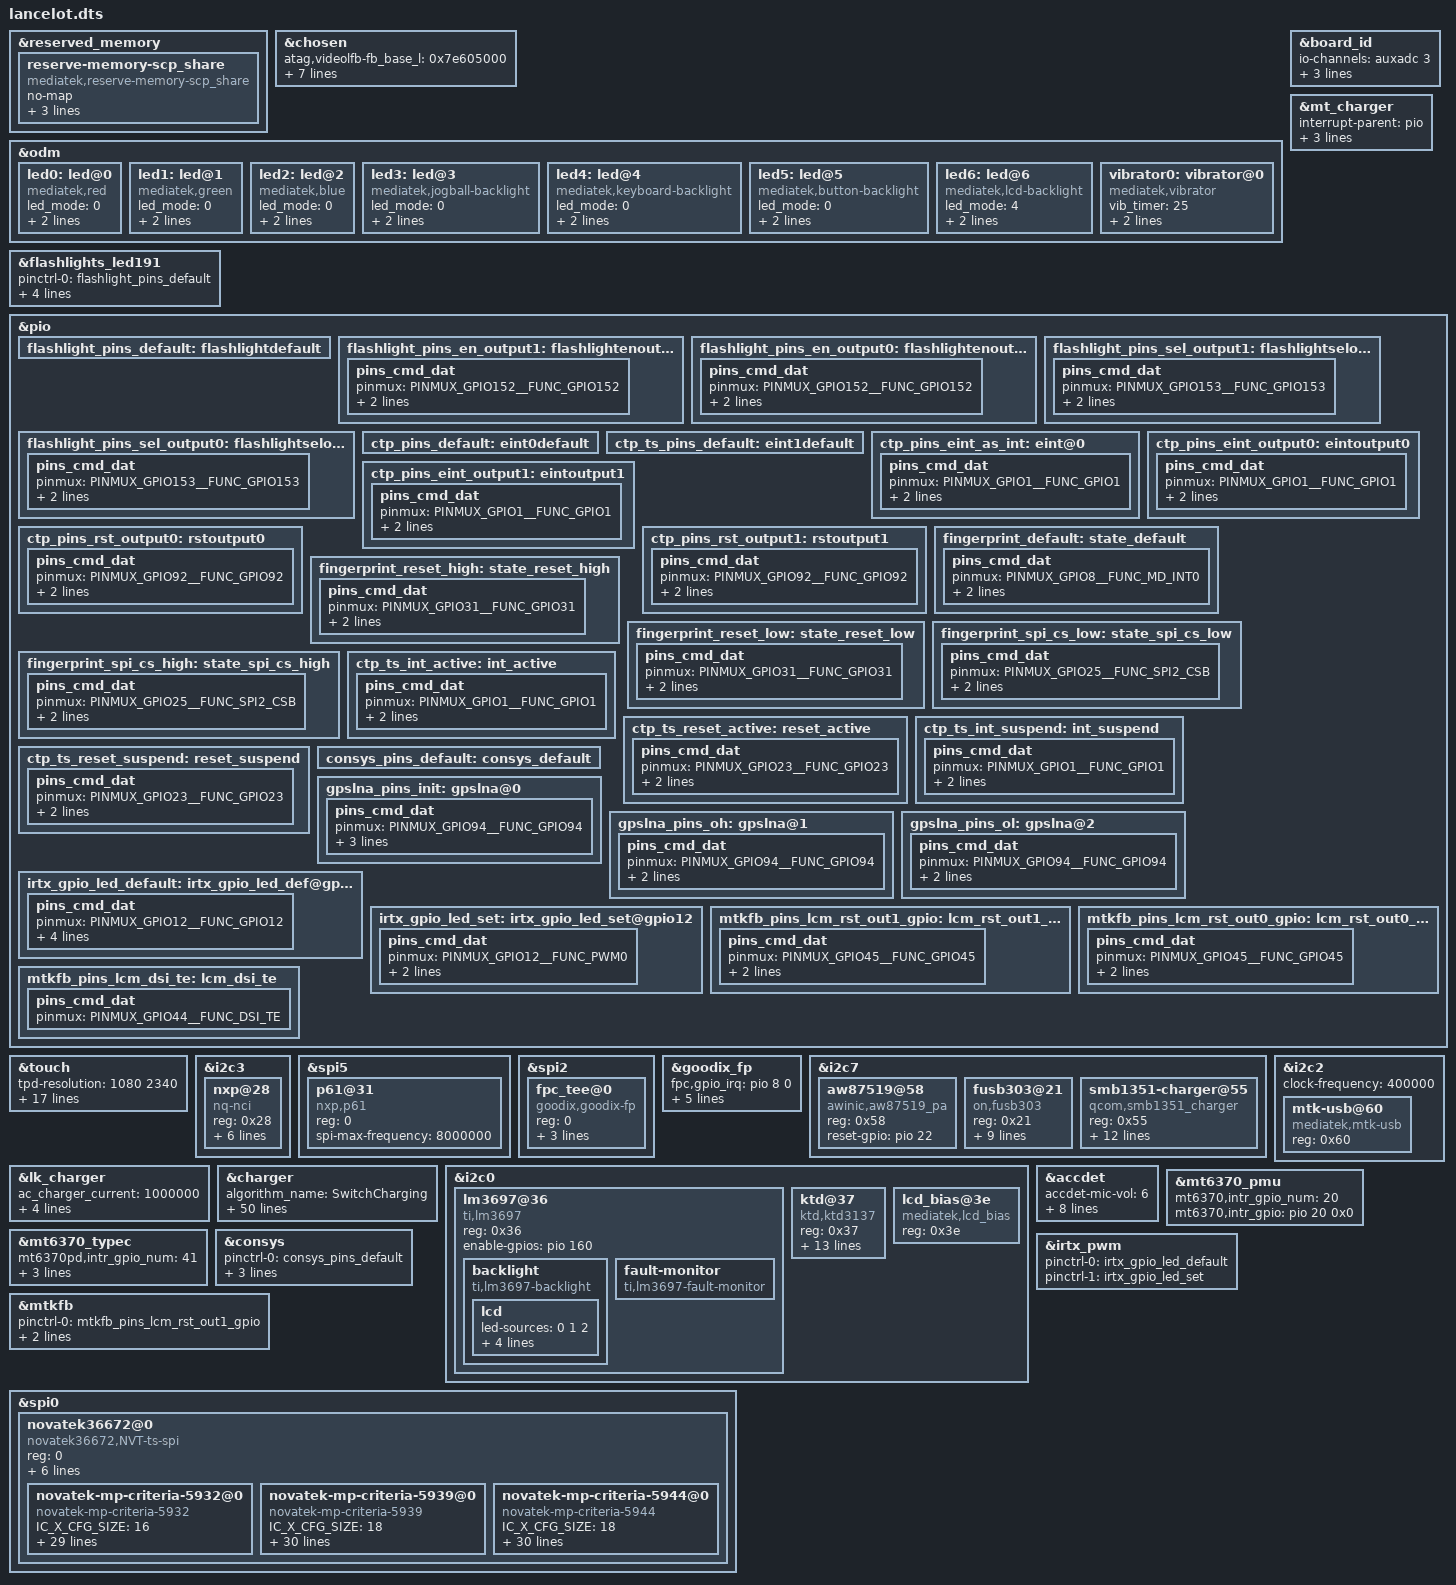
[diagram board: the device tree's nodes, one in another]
/*
 * Copyright (C) 2019 MediaTek Inc.
 *
 * This program is free software; you can redistribute it and/or modify
 * it under the terms of the GNU General Public License version 2 as
 * published by the Free Software Foundation.
 *
 * This program is distributed in the hope that it will be useful,
 * but WITHOUT ANY WARRANTY; without even the implied warranty of
 * MERCHANTABILITY or FITNESS FOR A PARTICULAR PURPOSE.
 * See http://www.gnu.org/licenses/gpl-2.0.html for more details.
 */

/dts-v1/;
/plugin/;
#include <dt-bindings/interrupt-controller/irq.h>
#include <dt-bindings/interrupt-controller/arm-gic.h>
#include <dt-bindings/pinctrl/mt6768-pinfunc.h>

&reserved_memory {
	reserve-memory-scp_share {
		compatible = "mediatek,reserve-memory-scp_share";
		no-map;
		size = <0 0x00d00000>;
		alignment = <0 0x1000000>;
		alloc-ranges = <0 0x40000000 0 0x50000000>;
	};
};

/* chosen */
&chosen {

	atag,videolfb-fb_base_l = <0x7e605000>;
	atag,videolfb-fb_base_h = <0x0>;
	atag,videolfb-islcmfound = <1>;
	atag,videolfb-islcm_inited = <0>;
	atag,videolfb-fps= <6000>;
	atag,videolfb-vramSize= <0x017e8000>;
	atag,videolfb-lcmname=
		"hx83112b_fhdp_dsi_cmd_auo_rt5081_drv";
};

&odm {
	led0:led@0 {
		compatible = "mediatek,red";
		led_mode = <0>;
		data = <1>;
		pwm_config = <0 0 0 0 0>;
	};
	led1:led@1 {
		compatible = "mediatek,green";
		led_mode = <0>;
		data = <1>;
		pwm_config = <0 0 0 0 0>;
	};
	led2:led@2 {
		compatible = "mediatek,blue";
		led_mode = <0>;
		data = <1>;
		pwm_config = <0 0 0 0 0>;
	};
	led3:led@3 {
		compatible = "mediatek,jogball-backlight";
		led_mode = <0>;
		data = <1>;
		pwm_config = <0 0 0 0 0>;
	};
	led4:led@4 {
		compatible = "mediatek,keyboard-backlight";
		led_mode = <0>;
		data = <1>;
		pwm_config = <0 0 0 0 0>;
	};
	led5:led@5 {
		compatible = "mediatek,button-backlight";
		led_mode = <0>;
		data = <1>;
		pwm_config = <0 0 0 0 0>;
	};
	led6:led@6 {
		compatible = "mediatek,lcd-backlight";
		led_mode = <4>;
		data = <1>;
		pwm_config = <0 3 0 0 0>;
	};
	vibrator0:vibrator@0 {
		compatible = "mediatek,vibrator";
		vib_timer = <25>;
		vib_limit = <9>;
		vib_vol= <11>;
	};
};

&board_id {
	io-channels = <&auxadc 3>;
	io-channel-names = "board_id-channel";
	hw_id-gpios = <&pio 158 0>;
	board_id2-gpios = <&pio 5 0>;
	board_id3-gpios = <&pio 6 0>;
	status = "okay";
};

&mt_charger {
	interrupt-parent = <&pio>;
	reverse-gpio = <&pio 91 0>;
	pinctrl-names = "reverse_high", "reverse_low";
	pinctrl-0 = <&reverse_high>;
	pinctrl-1 = <&reverse_low>;
};
/* flashlight start */
&flashlights_led191 {
	pinctrl-names = "default", "hw_ch0_high",
		"hw_ch0_low", "hw_ch1_high",
		"hw_ch1_low";
	pinctrl-0 = <&flashlight_pins_default>;
	pinctrl-1 = <&flashlight_pins_en_output1>;
	pinctrl-2 = <&flashlight_pins_en_output0>;
	pinctrl-3 = <&flashlight_pins_sel_output1>;
	pinctrl-4 = <&flashlight_pins_sel_output0>;
	status = "okay";
};
&pio {
	flashlight_pins_default: flashlightdefault {
	};
	flashlight_pins_en_output1: flashlightenoutput1 {
		pins_cmd_dat {
			pinmux = <PINMUX_GPIO152__FUNC_GPIO152>;
			slew-rate = <1>;
			output-high;
		};
	};
	flashlight_pins_en_output0: flashlightenoutput0 {
		pins_cmd_dat {
			pinmux = <PINMUX_GPIO152__FUNC_GPIO152>;
			slew-rate = <1>;
			output-low;
		};
	};
	flashlight_pins_sel_output1: flashlightseloutput1 {
		pins_cmd_dat {
			pinmux = <PINMUX_GPIO153__FUNC_GPIO153>;
			slew-rate = <1>;
			output-high;
		};
	};
	flashlight_pins_sel_output0: flashlightseloutput0 {
		pins_cmd_dat {
			pinmux = <PINMUX_GPIO153__FUNC_GPIO153>;
			slew-rate = <1>;
			output-low;
		};
	};
};
/* flashlight end*/
/* TOUCH start */
&touch {
	tpd-resolution = <1080 2340>;
	use-tpd-button = <0>;
	tpd-key-num = <3>;
	tpd-key-local= <139 172 158 0>;
	tpd-key-dim-local = <90 883 100 40 230
				883 100 40 370 883 100 40 0 0 0 0>;
	tpd-max-touch-num = <10>;
	tpd-filter-enable = <0>;
	tpd-filter-pixel-density = <168>;
	tpd-filter-custom-prameters = <0 0 0 0 0 0 0 0 0 0 0 0>;
	tpd-filter-custom-speed = <0 0 0>;
	pinctrl-names = "default", "state_eint_as_int",
		"state_eint_output0", "state_eint_output1",
		"state_rst_output0", "state_rst_output1";
	pinctrl-0 = <&ctp_pins_default>;
	pinctrl-1 = <&ctp_pins_eint_as_int>;
	pinctrl-2 = <&ctp_pins_eint_output0>;
	pinctrl-3 = <&ctp_pins_eint_output1>;
	pinctrl-4 = <&ctp_pins_rst_output0>;
	pinctrl-5 = <&ctp_pins_rst_output1>;
	status = "okay";
};
&pio {
	ctp_pins_default: eint0default {
	};
	ctp_ts_pins_default: eint1default {
	};
	ctp_pins_eint_as_int: eint@0 {
		pins_cmd_dat {
			pinmux = <PINMUX_GPIO1__FUNC_GPIO1>;
			slew-rate = <0>;
			bias-disable;
		};
	};
	ctp_pins_eint_output0: eintoutput0 {
		pins_cmd_dat {
			pinmux = <PINMUX_GPIO1__FUNC_GPIO1>;
			slew-rate = <1>;
			output-low;
		};
	};
	ctp_pins_eint_output1: eintoutput1 {
		pins_cmd_dat {
			pinmux = <PINMUX_GPIO1__FUNC_GPIO1>;
			slew-rate = <1>;
			output-high;
	};
	};
	ctp_pins_rst_output0: rstoutput0 {
		pins_cmd_dat {
				pinmux = <PINMUX_GPIO92__FUNC_GPIO92>;
				slew-rate = <1>;
				output-low;
			};
	};
	ctp_pins_rst_output1: rstoutput1 {
		pins_cmd_dat {
				pinmux = <PINMUX_GPIO92__FUNC_GPIO92>;
				slew-rate = <1>;
				output-high;
		};
	};

};
/* TOUCH end */

&i2c3 {
	status = "okay";
	nxp@28 {
		compatible = "nq-nci";
		reg = <0x28>;
		nq-irq = <&pio 9 0x00>;
		interrupt-parent = <&pio>;
		interrupts = <9 IRQ_TYPE_LEVEL_HIGH 9 0>;
		nq-ven = <&pio 159 0x0>;
		nq-firm = <&pio 17 0x0>;
		nq-clkreq = <&pio 11 0x0>;
		//nq-esepwr = <&tlmm 42 0x00>;
		interrupt-names = "irq_nfc";
	};

};

&spi5 {
	#address-cells = <1>;
	#size-cells = <0>;
	p61@31 {
		compatible = "nxp,p61";
		reg = <0>;
		spi-max-frequency = <8000000>;
		status = "okay";
	};
};


/* add goodix fingerprint start*/


&spi2 {
	status = "ok";
	#address-cells = <1>;
	#size-cells = <0>;
	fpc_tee@0 {
		compatible = "goodix,goodix-fp";
		reg = <0>;
		fpc,enable-wakeup;
		spi-max-frequency = <10000000>;
		netlink-event = <30>;
		status = "okay";
	};
};

&goodix_fp {
	fpc,gpio_irq = <&pio 8 0>;
	pinctrl-names = "default", "reset_high", "reset_low", "spi_cs_low", "spi_cs_high";
	pinctrl-0 = <&fingerprint_default>;
	pinctrl-1 = <&fingerprint_reset_high>;
	pinctrl-2 = <&fingerprint_reset_low>;
	pinctrl-3 = <&fingerprint_spi_cs_low>;
	pinctrl-4 = <&fingerprint_spi_cs_high>;
	status = "okay";
};

&pio {
	fingerprint_default: state_default {
		pins_cmd_dat {
			pinmux = <PINMUX_GPIO8__FUNC_MD_INT0>;
			slew-rate = <0>;
			bias-disable;
		};
	};
	fingerprint_reset_high: state_reset_high {
		pins_cmd_dat {
			pinmux = <PINMUX_GPIO31__FUNC_GPIO31>;
			slew-rate = <1>;
			output-high;
		};
	};
	fingerprint_reset_low: state_reset_low {
		pins_cmd_dat {
			pinmux = <PINMUX_GPIO31__FUNC_GPIO31>;
			slew-rate = <1>;
			output-low;
		};
	};

	fingerprint_spi_cs_low: state_spi_cs_low {
		pins_cmd_dat {
			pinmux = <PINMUX_GPIO25__FUNC_SPI2_CSB>;
			slew-rate = <1>;
			output-low;
		};
	};
	fingerprint_spi_cs_high: state_spi_cs_high {
		pins_cmd_dat {
			pinmux = <PINMUX_GPIO25__FUNC_SPI2_CSB>;
			slew-rate = <1>;
			output-high;
		};
	};

	ctp_ts_int_active: int_active {
		pins_cmd_dat {
			pinmux = <PINMUX_GPIO1__FUNC_GPIO1>;
			slew-rate = <0>;
			bias-pull-up = <11>;
		};
	};
	ctp_ts_reset_active: reset_active {
		pins_cmd_dat {
			pinmux = <PINMUX_GPIO23__FUNC_GPIO23>;
			slew-rate = <1>;
			output-high;
		};
	};
	ctp_ts_int_suspend: int_suspend {
		pins_cmd_dat {
			pinmux = <PINMUX_GPIO1__FUNC_GPIO1>;
			slew-rate = <1>;
			output-low;
		};
	};
	ctp_ts_reset_suspend: reset_suspend {
		pins_cmd_dat {
			pinmux = <PINMUX_GPIO23__FUNC_GPIO23>;
			slew-rate = <1>;
			output-low;
		};
	};
};
/* add goodix fingerprint end*/

/* AWINIC AW87519 Smart PA */
&i2c7 {
	aw87519@58 {
			compatible = "awinic,aw87519_pa";
			reg = <0x58>;
			reset-gpio = <&pio 22 0>;
			status = "okay";
	};
};
/* AWINIC AW87519 Smart PA End */

&i2c7 {
	fusb303@21 {
		status = "ok";
		compatible = "on,fusb303";
		reg = <0x21>;
		interrupt-parent = <&pio>;
		interrupts = <41 0x2>;
		fusb303,int-gpio = <&pio 41 0>;
		fusb303,init-mode = <20>;			/* trysnk, DRP */
		fusb303,host-current = <2>;			/* 180uA host current */
		fusb303,drp-toggle-time =  <1>;			/* 70ms */
		fusb303,drp-duty-time = <0>;			/* 60 duty time */
		fusb303,autosink-threshold = <1>;		/* 3P1V */
		fusb303,cc-debounce-time = <3>;			/* 150ms */
	};
};


&i2c7 {
	smb1351-charger@55 {
		compatible = "qcom,smb1351_charger";
		reg = <0x55>;
		interrupt-parent = <&pio>;
		interrupts = <20 IRQ_TYPE_EDGE_FALLING 20 0>;
		qcom,recharge-disabled;
		qcom,bc12_supported;
		/* qcom,smb1351_susp = <&pio 21 0x0>; */
		/* mi,connect_therm = <&pio 127 0x0>; */

		charger_name = "primary_chg";
		/*charger_name = "secondary_chg";*/
		ichg = <1800000>; /* uA */
		mivr = <4500000>; /* uV */
		cv = <4396000>; /* uV */
		ieoc = <200000>; /* uA */
		safety_timer = <12>; /* hour */
		en_st; /* safety timer */
		/* en_te; */
		en_wdt;
	};

};
&lk_charger  {
	/* charging current */
	ac_charger_current = <1000000>;
	non_std_ac_charger_current = <1000000>;

	/* battery temperature protection */
	temp_t4_threshold = <55>;
	temp_t3_threshold = <45>;
	temp_t1_threshold = <0>;
};

&charger {
	algorithm_name = "SwitchCharging";

	set_cap_delay = <10>;
	enable_sw_jeita;
	battery_cv = <4460000>;
	usb_charger_current_suspend = <0>;
	usb_charger_current_unconfigured = <70000>;
	usb_charger_current_configured = <500000>;
	usb_charger_current = <500000>;
	ac_charger_current = <2050000>;
	ac_charger_input_current = <2050000>;
	non_std_ac_charger_current = <1000000>;
	charging_host_charger_current = <1500000>;
	apple_1_0a_charger_current = <650000>;
	apple_2_1a_charger_current = <800000>;
	ta_ac_charger_current = <2050000>;
	hvdcp_charger_current = <3000000>;

	pd_vbus_upper_bound = <9000000>;


	/* sw jeita */
	jeita_temp_above_t4_cv = <4100000>;
	jeita_temp_t3_to_t4_cv = <4100000>;
	jeita_temp_t2_to_t3_cv = <4460000>;
	jeita_temp_t1_to_t2_cv = <4460000>;
	jeita_temp_t0_to_t1_cv = <4460000>;
	jeita_temp_below_t0_cv = <4460000>;


	jeita_temp_t3_to_t4_cc = <2400000>;
	jeita_temp_t2_to_t3_cc = <3000000>;
	jeita_temp_t1_to_t2_cc = <2400000>;
	jeita_temp_t0_to_t1_cc = <1000000>;

	temp_t4_thres = <55>;
	temp_t4_thres_minus_x_degree = <53>;
	temp_t3_thres = <45>;
	temp_t3_thres_minus_x_degree = <43>;
	temp_t2_thres = <15>;
	temp_t2_thres_plus_x_degree = <13>;
	temp_t1_thres = <5>;
	temp_t1_thres_plus_x_degree = <4>;
	temp_t0_thres = <0>;
	temp_t0_thres_plus_x_degree = <0>;
	temp_neg_10_thres = <0>;

	/* battery temperature protection */
	enable_min_charge_temp;
	min_charge_temp = <0>;
	min_charge_temp_plus_x_degree = <2>;
	max_charge_temp = <55>;
	max_charge_temp_minus_x_degree = <53>;

	qcom,thermal-mitigation-dcp
		= <1800000 1800000 1800000 1800000 1800000 1800000 1800000
		1800000 1800000 1800000 1800000 1800000 1600000 1400000
		1200000 1000000>;
	qcom,thermal-mitigation-qc3
		= <2700000 2570000 2400000 2270000 2120000 1965000 1820000
		1650000 1500000 1375000 1225000 1100000 975000 825000
		675000 475000>;
	qcom,thermal-mitigation-qc2
		= <1625000 1625000 1625000 1625000 1625000 1525000 1425000
		1325000 1225000 1125000 1025500 925000 825000 725000
		625000 525000>;
	qcom,thermal-mitigation-pd-base
		= <3000000 2800000 2600000 2400000 2200000 2000000 1800000
		1600000 1600000 1400000 1200000 1100000 1000000 900000
		752500 525000>;
};




&i2c2 {
	clock-frequency = <400000>;

	mtk-usb@60 {
		compatible = "mediatek,mtk-usb";
		reg = <0x60>;
		status = "okay";
	};
};

&i2c0 {
	lm3697@36 {
		compatible = "ti,lm3697";
		reg = <0x36>;

		status = "okay";
		enable-gpios = <&pio 160 0>;

		backlight {
			compatible = "ti,lm3697-backlight";

			lcd {
				led-sources = <0 1 2>;
				ramp-up-msec = <200>;
				ramp-down-msec = <200>;
				pwm-period = <0>;
				default-brightness-level = <255>;
			};
		};
		fault-monitor {
			compatible = "ti,lm3697-fault-monitor";
		};
	};

	ktd@37 {
	compatible = "ktd,ktd3137";
	reg = <0x37>;
	status = "okay";
	/*ktd,pwm-mode; */
	ktd,using-lsb = <1>;
	ktd,pwm-frequency = <100>;
	ktd,bl-fscal-led = <0x98>;/*default 20.2mA*/
	ktd,turn-on-ramp = <0>;
	ktd,turn-off-ramp = <0>;
	ktd,pwm-trans-dim = <0>;
	ktd,i2c-trans-dim = <0>;
	ktd,bl-channel = <2>;
	ktd,ovp-level = <32>;/*default 32v*/
	ktd,switching-frequency = <1000>; /*default 1000kHz*/
	ktd,inductor-current = <2600>; //default 2600mA
	ktd,linear_ramp = <1>; /*default is exponential*/
	ktd,linear_backlight = <1>; /*default is exponential*/
    };

	lcd_bias@3e {
		compatible = "mediatek,lcd_bias";
		reg = <0x3e>;
		status = "okay";
	};
};

/* accdet start */
&accdet {
	/* accdet micbias voltage: 0x07,2.7v;0x05,2.5v;0x02,1.9v */
	accdet-mic-vol = <6>;
	headset-mode-setting = <0x500 0x500 1 0x1f0 0x800 0x800 0x20 0x44>;
	accdet-plugout-debounce = <1>;
	/*1:ACC mode, 2:low cost without in bias, 6:low cost with in bias*/
	accdet-mic-mode = <1>;
	/* eint_level_trigger: 8,LEVEL_LOW(DEF) ;4,LV_HIGH;others,LV_LOW */
	headset-eint-level-pol = <8>;
	/*0--MD_MAX--UP_MAX--DW_MAX*/
	headset-three-key-threshold = <0 80 220 400>;
	headset-three-key-threshold-CDD = <0 121 192 600>;
	/*0--MD_MAX--VOICE_MAX--UP_MAX--DW_MAX*/
	headset-four-key-threshold = <0 58 121 192 400>;
	status = "okay";
};
/* accdet end */

&mt6370_pmu {
	mt6370,intr_gpio_num = <20>; /* direct defined GPIO num */
	mt6370,intr_gpio = <&pio 20 0x0>;
};
&mt6370_typec {
	mt6370pd,intr_gpio_num = <41>; /* direct defined GPIO num */
	mt6370pd,intr_gpio = <&pio 41 0x0>;
	mt6370pd,usb_switch_gpio_num = <91>; /* direct defined GPIO num */
	mt6370pd,usb_switch_gpio = <&pio 91 0x0>;
};

/* CONSYS GPIO standardization */
&pio {
	consys_pins_default: consys_default {
	};
	gpslna_pins_init: gpslna@0 {
		pins_cmd_dat {
			pinmux = <PINMUX_GPIO94__FUNC_GPIO94>;
			slew-rate = <0>;
			bias-disable;
			output-low;
		};
	};
	gpslna_pins_oh: gpslna@1 {
		pins_cmd_dat {
			pinmux = <PINMUX_GPIO94__FUNC_GPIO94>;
			slew-rate = <1>;
			output-high;
		};
	};
	gpslna_pins_ol: gpslna@2 {
		pins_cmd_dat {
			pinmux = <PINMUX_GPIO94__FUNC_GPIO94>;
			slew-rate = <1>;
			output-low;
		};
	};
};
&consys {
	pinctrl-names = "default", "gps_lna_state_init",
		"gps_lna_state_oh", "gps_lna_state_ol";
	pinctrl-0 = <&consys_pins_default>;
	pinctrl-1 = <&gpslna_pins_init>;
	pinctrl-2 = <&gpslna_pins_oh>;
	pinctrl-3 = <&gpslna_pins_ol>;
	status = "okay";
};
/* CONSYS end */

/* IRTX GPIO Start */
&irtx_pwm {
	pinctrl-names = "irtx_gpio_led_default", "irtx_gpio_led_set";
	pinctrl-0 = <&irtx_gpio_led_default>;
	pinctrl-1 = <&irtx_gpio_led_set>;
	status = "okay";
};
&pio {
	/* IRTX GPIO Settings -Start */
	/* default: GPIO0, output, high */
	irtx_gpio_led_default:irtx_gpio_led_def@gpio12 {
		pins_cmd_dat {
			pinmux = <PINMUX_GPIO12__FUNC_GPIO12>;
			slew-rate = <1>;
			bias-disable;
			output-low;
			input-schmitt-enable = <0>;
		};
	};

	irtx_gpio_led_set:irtx_gpio_led_set@gpio12 {
		pins_cmd_dat {
			pinmux = <PINMUX_GPIO12__FUNC_PWM0>;
			slew-rate = <1>;
			output-high;
		};
	};
}; /* IRTX GPIO Settings -End */

/* DISPSYS GPIO standardization */
&pio {
	mtkfb_pins_lcm_rst_out1_gpio: lcm_rst_out1_gpio {
		pins_cmd_dat {
			pinmux = <PINMUX_GPIO45__FUNC_GPIO45>;
			slew-rate = <1>;
			output-high;
		};
	};

	mtkfb_pins_lcm_rst_out0_gpio: lcm_rst_out0_gpio {
		pins_cmd_dat {
			pinmux = <PINMUX_GPIO45__FUNC_GPIO45>;
			slew-rate = <1>;
			output-low;
		};
	};

	mtkfb_pins_lcm_dsi_te: lcm_dsi_te {
		pins_cmd_dat {
			pinmux = <PINMUX_GPIO44__FUNC_DSI_TE>;
		};
	};
};

&mtkfb {
	pinctrl-names =
		"lcm_rst_out1_gpio", "lcm_rst_out0_gpio",
		"mode_te_te";
	pinctrl-0 = <&mtkfb_pins_lcm_rst_out1_gpio>;
	pinctrl-1 = <&mtkfb_pins_lcm_rst_out0_gpio>;
	pinctrl-2 = <&mtkfb_pins_lcm_dsi_te>;
	status = "okay";
};

&spi0 {
	status = "ok";

	/* Novatek device tree node */
	novatek36672@0 {
	compatible = "novatek36672,NVT-ts-spi","focaltech8719P,FTS-ts-spi";
	reg = <0>; //Same as CS ID
	status = "ok";

	spi-max-frequency = <8000000>;	//4800000,9600000,15000000,19200000
	novatek,reset-gpio = <&pio 92 0x00>;
	novatek,irq-gpio = <&pio 1 0x2001>;

	/* 525 */
	//novatek,swrst-n8-addr = <0x01F01A>;

	/* 672A, 525B, 675, 526, 672C */
	novatek,swrst-n8-addr = <0x03F0FE>;
	novatek,spi-rd-fast-addr = <0x03F310>;

	/* MP */
		novatek,mp-support-dt;

		novatek-mp-criteria-5932@0 {
			#address-cells = <1>;
			#size-cells = <0>;
			compatible = "novatek-mp-criteria-5932";

			/* MP Config */
			IC_X_CFG_SIZE = <16>;
			IC_Y_CFG_SIZE = <36>;
			IC_KEY_CFG_SIZE = <4>;
			X_Channel = <16>;
			Y_Channel = <36>;
			AIN_X = <0 1 2 3 4 5 6 7 8 9 10 11 12 13 14 15>;
			AIN_Y = <0 1 2 3 4 5 6 7 8 9 10 11 12 13 14 15 16 17
						18 19 20 21 22 23 24 25 26 27 28 29 30 31 32 33 34 35>;
			AIN_KEY = <0 1 2 0xFF>;

			/* MP Criteria */
			PS_Config_Lmt_Short_Rawdata_P = <
				14000	14000	14000	14000	14000	14000	14000	14000	14000	14000	14000	14000	14000	14000	14000	14000
				14000	14000	14000	14000	14000	14000	14000	14000	14000	14000	14000	14000	14000	14000	14000	14000
				14000	14000	14000	14000	14000	14000	14000	14000	14000	14000	14000	14000	14000	14000	14000	14000
				14000	14000	14000	14000	14000	14000	14000	14000	14000	14000	14000	14000	14000	14000	14000	14000
				14000	14000	14000	14000	14000	14000	14000	14000	14000	14000	14000	14000	14000	14000	14000	14000
				14000	14000	14000	14000	14000	14000	14000	14000	14000	14000	14000	14000	14000	14000	14000	14000
				14000	14000	14000	14000	14000	14000	14000	14000	14000	14000	14000	14000	14000	14000	14000	14000
				14000	14000	14000	14000	14000	14000	14000	14000	14000	14000	14000	14000	14000	14000	14000	14000
				14000	14000	14000	14000	14000	14000	14000	14000	14000	14000	14000	14000	14000	14000	14000	14000
				14000	14000	14000	14000	14000	14000	14000	14000	14000	14000	14000	14000	14000	14000	14000	14000
				14000	14000	14000	14000	14000	14000	14000	14000	14000	14000	14000	14000	14000	14000	14000	14000
				14000	14000	14000	14000	14000	14000	14000	14000	14000	14000	14000	14000	14000	14000	14000	14000
				14000	14000	14000	14000	14000	14000	14000	14000	14000	14000	14000	14000	14000	14000	14000	14000
				14000	14000	14000	14000	14000	14000	14000	14000	14000	14000	14000	14000	14000	14000	14000	14000
				14000	14000	14000	14000	14000	14000	14000	14000	14000	14000	14000	14000	14000	14000	14000	14000
				14000	14000	14000	14000	14000	14000	14000	14000	14000	14000	14000	14000	14000	14000	14000	14000
				14000	14000	14000	14000	14000	14000	14000	14000	14000	14000	14000	14000	14000	14000	14000	14000
				14000	14000	14000	14000	14000	14000	14000	14000	14000	14000	14000	14000	14000	14000	14000	14000
				14000	14000	14000	14000	14000	14000	14000	14000	14000	14000	14000	14000	14000	14000	14000	14000
				14000	14000	14000	14000	14000	14000	14000	14000	14000	14000	14000	14000	14000	14000	14000	14000
				14000	14000	14000	14000	14000	14000	14000	14000	14000	14000	14000	14000	14000	14000	14000	14000
				14000	14000	14000	14000	14000	14000	14000	14000	14000	14000	14000	14000	14000	14000	14000	14000
				14000	14000	14000	14000	14000	14000	14000	14000	14000	14000	14000	14000	14000	14000	14000	14000
				14000	14000	14000	14000	14000	14000	14000	14000	14000	14000	14000	14000	14000	14000	14000	14000
				14000	14000	14000	14000	14000	14000	14000	14000	14000	14000	14000	14000	14000	14000	14000	14000
				14000	14000	14000	14000	14000	14000	14000	14000	14000	14000	14000	14000	14000	14000	14000	14000
				14000	14000	14000	14000	14000	14000	14000	14000	14000	14000	14000	14000	14000	14000	14000	14000
				14000	14000	14000	14000	14000	14000	14000	14000	14000	14000	14000	14000	14000	14000	14000	14000
				14000	14000	14000	14000	14000	14000	14000	14000	14000	14000	14000	14000	14000	14000	14000	14000
				14000	14000	14000	14000	14000	14000	14000	14000	14000	14000	14000	14000	14000	14000	14000	14000
				14000	14000	14000	14000	14000	14000	14000	14000	14000	14000	14000	14000	14000	14000	14000	14000
				14000	14000	14000	14000	14000	14000	14000	14000	14000	14000	14000	14000	14000	14000	14000	14000
				14000	14000	14000	14000	14000	14000	14000	14000	14000	14000	14000	14000	14000	14000	14000	14000
				14000	14000	14000	14000	14000	14000	14000	14000	14000	14000	14000	14000	14000	14000	14000	14000
				14000	14000	14000	14000	14000	14000	14000	14000	14000	14000	14000	14000	14000	14000	14000	14000
				14000	14000	14000	14000	14000	14000	14000	14000	14000	14000	14000	14000	14000	14000	14000	14000
				14008 14008 14008>;

			PS_Config_Lmt_Short_Rawdata_N = <
				11300	11300	11300	11300	11300	11300	11300	11300	11300	11300	11300	11300	11300	11300	11300	11300
				11300	11300	11300	11300	11300	11300	11300	11300	11300	11300	11300	11300	11300	11300	11300	11300
				11300	11300	11300	11300	11300	11300	11300	11300	11300	11300	11300	11300	11300	11300	11300	11300
				11300	11300	11300	11300	11300	11300	11300	11300	11300	11300	11300	11300	11300	11300	11300	11300
				11300	11300	11300	11300	11300	11300	11300	11300	11300	11300	11300	11300	11300	11300	11300	11300
				11300	11300	11300	11300	11300	11300	11300	11300	11300	11300	11300	11300	11300	11300	11300	11300
				11300	11300	11300	11300	11300	11300	11300	11300	11300	11300	11300	11300	11300	11300	11300	11300
				11300	11300	11300	11300	11300	11300	11300	11300	11300	11300	11300	11300	11300	11300	11300	11300
				11300	11300	11300	11300	11300	11300	11300	11300	11300	11300	11300	11300	11300	11300	11300	11300
				11300	11300	11300	11300	11300	11300	11300	11300	11300	11300	11300	11300	11300	11300	11300	11300
				11300	11300	11300	11300	11300	11300	11300	11300	11300	11300	11300	11300	11300	11300	11300	11300
				11300	11300	11300	11300	11300	11300	11300	11300	11300	11300	11300	11300	11300	11300	11300	11300
				11300	11300	11300	11300	11300	11300	11300	11300	11300	11300	11300	11300	11300	11300	11300	11300
				11300	11300	11300	11300	11300	11300	11300	11300	11300	11300	11300	11300	11300	11300	11300	11300
				11300	11300	11300	11300	11300	11300	11300	11300	11300	11300	11300	11300	11300	11300	11300	11300
				11300	11300	11300	11300	11300	11300	11300	11300	11300	11300	11300	11300	11300	11300	11300	11300
				11300	11300	11300	11300	11300	11300	11300	11300	11300	11300	11300	11300	11300	11300	11300	11300
				11300	11300	11300	11300	11300	11300	11300	11300	11300	11300	11300	11300	11300	11300	11300	11300
				11300	11300	11300	11300	11300	11300	11300	11300	11300	11300	11300	11300	11300	11300	11300	11300
				11300	11300	11300	11300	11300	11300	11300	11300	11300	11300	11300	11300	11300	11300	11300	11300
				11300	11300	11300	11300	11300	11300	11300	11300	11300	11300	11300	11300	11300	11300	11300	11300
				11300	11300	11300	11300	11300	11300	11300	11300	11300	11300	11300	11300	11300	11300	11300	11300
				11300	11300	11300	11300	11300	11300	11300	11300	11300	11300	11300	11300	11300	11300	11300	11300
				11300	11300	11300	11300	11300	11300	11300	11300	11300	11300	11300	11300	11300	11300	11300	11300
				11300	11300	11300	11300	11300	11300	11300	11300	11300	11300	11300	11300	11300	11300	11300	11300
				11300	11300	11300	11300	11300	11300	11300	11300	11300	11300	11300	11300	11300	11300	11300	11300
				11300	11300	11300	11300	11300	11300	11300	11300	11300	11300	11300	11300	11300	11300	11300	11300
				11300	11300	11300	11300	11300	11300	11300	11300	11300	11300	11300	11300	11300	11300	11300	11300
				11300	11300	11300	11300	11300	11300	11300	11300	11300	11300	11300	11300	11300	11300	11300	11300
				11300	11300	11300	11300	11300	11300	11300	11300	11300	11300	11300	11300	11300	11300	11300	11300
				11300	11300	11300	11300	11300	11300	11300	11300	11300	11300	11300	11300	11300	11300	11300	11300
				11300	11300	11300	11300	11300	11300	11300	11300	11300	11300	11300	11300	11300	11300	11300	11300
				11300	11300	11300	11300	11300	11300	11300	11300	11300	11300	11300	11300	11300	11300	11300	11300
				11300	11300	11300	11300	11300	11300	11300	11300	11300	11300	11300	11300	11300	11300	11300	11300
				11300	11300	11300	11300	11300	11300	11300	11300	11300	11300	11300	11300	11300	11300	11300	11300
				11300	11300	11300	11300	11300	11300	11300	11300	11300	11300	11300	11300	11300	11300	11300	11300
				10000 10000 10000>;

			PS_Config_Lmt_Open_Rawdata_P = <
				2674	4147	4159	4212	4166	4193	3576	65535	65535	3653	4213	4269	4239	4318	4215	2773
				4095	4182	4119	4177	4127	4160	4110	4264	4218	4207	4161	4208	4180	4257	4226	4231
				4204	4208	4147	4201	4151	4192	4141	4168	4168	4237	4194	4240	4216	4291	4253	4321
				4178	4212	4152	4208	4156	4197	4140	4166	4175	4241	4206	4249	4227	4297	4263	4310
				4201	4224	4168	4220	4160	4201	4146	4173	4194	4260	4226	4265	4246	4314	4276	4326
				4201	4230	4177	4229	4168	4208	4150	4174	4191	4254	4221	4262	4243	4309	4273	4330
				4211	4245	4187	4239	4179	4224	4163	4187	4206	4264	4236	4279	4258	4324	4288	4320
				4212	4246	4189	4239	4182	4225	4163	4187	4212	4268	4243	4287	4265	4328	4296	4324
				4221	4234	4178	4226	4171	4217	4154	4175	4210	4265	4240	4286	4260	4321	4287	4329
				4221	4243	4188	4232	4178	4222	4157	4184	4232	4272	4234	4296	4269	4325	4293	4324
				4203	4248	4196	4236	4178	4225	4159	4189	4234	4278	4239	4300	4277	4335	4297	4325
				4208	4253	4204	4246	4187	4231	4165	4196	4235	4278	4239	4301	4274	4330	4293	4324
				4208	4248	4198	4239	4182	4227	4159	4189	4231	4273	4239	4301	4272	4330	4295	4321
				4211	4257	4204	4244	4185	4232	4163	4201	4240	4282	4249	4311	4277	4334	4295	4307
				4202	4236	4197	4234	4174	4218	4151	4194	4237	4282	4248	4310	4276	4334	4288	4287
				4207	4243	4199	4239	4178	4222	4161	4201	4225	4265	4235	4296	4258	4320	4271	4284
				4193	4235	4192	4230	4170	4213	4152	4208	4204	4253	4222	4284	4249	4306	4253	4284
				4194	4224	4183	4222	4163	4208	4147	4201	4213	4253	4222	4283	4243	4302	4248	4287
				4188	4229	4183	4222	4163	4208	4147	4199	4207	4250	4221	4282	4239	4297	4244	4273
				4165	4224	4178	4218	4157	4204	4144	4196	4202	4241	4213	4273	4230	4290	4234	4272
				4168	4206	4156	4197	4137	4185	4126	4177	4191	4239	4204	4263	4220	4279	4218	4272
				4166	4192	4146	4183	4121	4166	4112	4157	4185	4237	4202	4259	4213	4276	4213	4260
				4149	4191	4140	4179	4117	4166	4113	4164	4180	4236	4201	4257	4213	4272	4217	4239
				4132	4179	4128	4168	4103	4152	4100	4151	4173	4231	4194	4251	4203	4262	4206	4236
				4130	4169	4121	4165	4103	4150	4099	4149	4156	4216	4173	4229	4184	4239	4184	4221
				4119	4150	4103	4145	4083	4133	4085	4133	4155	4212	4173	4229	4180	4236	4182	4212
				4108	4155	4103	4146	4083	4133	4084	4133	4136	4199	4155	4211	4165	4216	4163	4206
				4089	4131	4080	4119	4057	4114	4061	4112	4122	4185	4138	4192	4146	4199	4150	4191
				4094	4116	4062	4103	4041	4095	4044	4093	4116	4178	4133	4188	4145	4196	4147	4170
				4074	4099	4047	4089	4027	4080	4027	4076	4098	4159	4114	4171	4130	4180	4132	4157
				4058	4089	4033	4076	4017	4072	4023	4074	4072	4133	4089	4145	4103	4154	4107	4145
				3738	4081	3731	4070	3714	4064	3717	4062	3765	4126	3776	4136	3792	4142	3797	4128
				3736	3751	3699	3743	3685	3733	3689	3741	3754	3806	3765	3823	3782	3832	3788	3835
				3728	3737	3686	3731	3672	3719	3677	3724	3733	3785	3743	3802	3759	3810	3770	3864
				3610	3719	3667	3712	3655	3700	3663	3712	3718	3768	3727	3785	3740	3792	3752	3714
				2202	3661	3672	3721	3661	3708	3666	3716	3740	3787	3747	3808	3765	3813	3713	2301
				5120 5120 5120>;

			PS_Config_Lmt_Open_Rawdata_N = <
				1537	2384	2390	2421	2395	2410	2055	(-65535)	(-65535)	2100	2422	2454	2436	2482	2422	1594
				2354	2403	2368	2400	2372	2391	2363	2451	2425	2418	2392	2419	2403	2446	2429	2432
				2417	2419	2384	2414	2386	2409	2380	2395	2395	2436	2411	2437	2423	2466	2444	2484
				2401	2421	2387	2419	2389	2412	2379	2395	2400	2438	2417	2442	2430	2470	2450	2477
				2414	2427	2395	2425	2391	2414	2383	2398	2411	2449	2429	2452	2441	2479	2457	2487
				2414	2431	2400	2430	2395	2419	2385	2399	2409	2445	2426	2449	2438	2476	2456	2489
				2420	2440	2406	2436	2402	2427	2392	2406	2417	2451	2435	2460	2447	2485	2465	2483
				2421	2441	2408	2436	2403	2428	2392	2406	2421	2453	2438	2464	2452	2487	2469	2485
				2426	2433	2401	2429	2398	2424	2387	2400	2419	2452	2437	2463	2449	2484	2464	2488
				2426	2438	2407	2433	2401	2427	2390	2405	2433	2455	2433	2469	2454	2486	2468	2485
				2416	2441	2411	2435	2401	2428	2390	2408	2433	2459	2436	2471	2458	2492	2470	2486
				2419	2444	2417	2441	2406	2432	2394	2411	2434	2459	2436	2472	2457	2489	2468	2485
				2419	2441	2413	2436	2403	2430	2390	2408	2432	2456	2436	2472	2455	2489	2468	2484
				2420	2446	2417	2439	2406	2433	2392	2414	2437	2461	2442	2478	2458	2491	2468	2476
				2415	2435	2412	2433	2399	2425	2386	2411	2436	2461	2441	2477	2457	2491	2465	2464
				2418	2438	2414	2436	2401	2427	2392	2414	2428	2452	2434	2469	2447	2483	2454	2463
				2410	2434	2409	2431	2397	2422	2387	2419	2417	2444	2427	2463	2442	2475	2444	2463
				2411	2427	2404	2427	2392	2419	2384	2414	2422	2444	2427	2462	2438	2473	2441	2464
				2407	2430	2404	2427	2392	2419	2384	2414	2418	2443	2426	2461	2436	2470	2439	2456
				2394	2427	2401	2425	2390	2417	2381	2411	2415	2438	2422	2456	2431	2465	2433	2455
				2395	2417	2389	2412	2378	2406	2371	2400	2409	2436	2417	2450	2425	2460	2425	2455
				2395	2409	2383	2404	2368	2395	2363	2390	2406	2436	2415	2448	2422	2457	2422	2449
				2384	2409	2379	2402	2366	2395	2364	2393	2403	2435	2414	2446	2422	2455	2424	2436
				2375	2402	2373	2395	2358	2387	2357	2386	2398	2432	2411	2444	2416	2449	2417	2435
				2373	2396	2368	2394	2358	2385	2356	2384	2389	2423	2398	2430	2405	2436	2405	2426
				2368	2385	2358	2382	2346	2376	2348	2376	2388	2421	2398	2430	2403	2435	2403	2421
				2361	2388	2358	2383	2346	2376	2347	2376	2377	2414	2388	2420	2394	2423	2392	2417
				2350	2374	2345	2368	2332	2365	2334	2363	2369	2406	2379	2409	2383	2414	2385	2409
				2353	2365	2335	2358	2322	2354	2325	2352	2365	2401	2376	2407	2382	2411	2384	2397
				2341	2356	2326	2350	2314	2345	2314	2343	2355	2390	2365	2398	2373	2403	2375	2390
				2333	2350	2318	2343	2308	2341	2312	2341	2341	2376	2350	2382	2358	2387	2360	2382
				2149	2346	2144	2339	2135	2336	2136	2335	2164	2371	2171	2377	2179	2381	2182	2373
				2147	2156	2126	2152	2118	2146	2120	2150	2157	2187	2164	2198	2173	2203	2177	2204
				2143	2148	2119	2144	2111	2138	2114	2141	2146	2176	2152	2185	2160	2190	2167	2221
				2075	2138	2108	2133	2100	2127	2106	2133	2137	2165	2142	2176	2149	2179	2157	2135
				1265	2104	2111	2138	2104	2131	2107	2135	2149	2176	2154	2189	2164	2192	2134	1322
				(-511) (-511) (-511)>;

			PS_Config_Lmt_FW_Rawdata_P = <
				2052	2052	2067	2067	2072	2057	2068	2059	2077	2061	2043	2089	2041	2046	2094	2080
				2078	2035	2024	2083	2089	2024	2011	2095	2093	2046	2054	2095	2041	2047	2074	2073
				2052	2082	2046	2067	2061	2056	2065	2056	2078	2052	2041	2063	2072	2044	2070	2043
				2054	2077	2077	2046	2067	2072	2044	2048	2072	2056	2070	2069	2052	2043	2067	2038
				2055	2056	2093	2038	2090	2067	2074	2086	2081	2054	2083	2041	2067	2074	2065	2077
				2047	2087	2103	2083	2026	2115	2104	2112	2052	2102	2033	2096	2034	2102	2055	2026
				2061	2091	2016	2130	2003	2051	2009	2076	2043	1999	2098	2042	2102	2042	2064	2017
				2015	2057	2099	2054	2056	2070	2055	2068	2077	2029	2085	2050	2077	2054	2085	2078
				2018	2055	2055	2039	2082	2065	2054	2080	2061	2112	2070	2031	2069	2089	2069	2015
				2072	2059	2083	2099	2044	2052	2051	2048	2026	2085	2034	2099	2029	2087	2078	2068
				2055	2068	2056	2043	2064	2026	2065	2076	2056	2081	2046	2037	2061	2069	2052	2073
				2055	2065	2047	2060	2060	2034	2067	2069	2089	2103	2028	2025	2085	2093	2026	2063
				2044	2064	2050	2067	2038	2025	2039	2051	2063	2047	2074	2063	2060	2051	2051	2064
				2037	2057	2073	2093	2038	2034	2061	2098	2072	2089	2054	2051	2055	2044	2070	2005
				2025	2026	2076	2028	2093	2090	2031	2086	2096	2093	2061	2054	2067	2054	2069	2044
				2047	2064	2059	2060	2039	2037	2074	2081	2086	2083	2050	2022	2087	2063	2035	2042
				2050	2061	2082	2031	2065	2073	2070	2059	2035	2100	2026	2033	2103	2030	2057	2038
				2059	2064	2056	2082	2078	2082	2047	2074	2076	2059	2073	2050	2061	2085	2031	2059
				2055	2041	2077	2069	2090	2070	2029	2068	2043	2052	2067	2080	2043	2065	2055	2089
				2021	2067	2083	2048	2056	2065	2085	2042	2064	2052	2073	2081	2050	2074	2063	2063
				2056	2056	2031	2085	2035	2056	2061	2061	2039	2061	2050	2046	2063	2052	2076	2025
				2054	2082	2060	2064	2056	2102	2073	2078	2061	2081	2055	2057	2065	2037	2070	2059
				2030	2057	2044	2086	2030	2029	2078	2100	2096	2018	2102	2020	2082	2099	2038	2050
				2060	2081	2037	2090	2034	2072	2089	2015	2041	2041	2072	2035	2048	2094	2047	2050
				2042	2102	2034	2046	2034	2074	2037	2052	2042	2052	2041	2063	2055	2052	2043	2037
				2013	2039	2067	2057	2067	2059	2056	2078	2074	2095	2060	2102	2069	2057	2072	2070
				2031	2080	2035	2080	2048	2072	2064	2085	2064	2082	2070	2073	2087	2082	2041	2065
				2048	2051	2052	2057	2082	2037	2067	2065	2090	2051	2077	2050	2048	2083	2044	2090
				2033	2060	2067	2070	2080	2051	2039	2096	2044	2080	2030	2077	2046	2082	2052	2046
				2047	2074	2024	2087	2041	2061	2096	2069	2059	2055	2064	2068	2082	2041	2035	2060
				2044	2093	2050	2068	2034	2050	2060	2051	2067	2096	2068	2093	2052	2035	2100	2103
				2077	2022	2070	2042	2076	2007	2022	2024	2044	2081	2043	2041	2063	2072	2034	2070
				2074	2060	2096	2050	2065	2056	2087	2041	2052	2057	2060	2078	2048	2085	2082	2059
				2076	2100	2078	2026	2113	2022	2009	2047	2061	2051	2054	2089	2103	2065	2016	2060
				2061	2044	2074	2061	2093	2061	2050	2042	2077	2086	2094	2024	2087	2030	2077	2050
				2078	2060	2018	2035	2074	2030	2078	2064	2073	2048	2038	2076	2090	2048	2068	2065
				2560 2560 2560>;

			PS_Config_Lmt_FW_Rawdata_N = <
				1105	1105	1113	1113	1115	1108	1113	1108	1118	1110	1100	1124	1099	1101	1127	1120
				1119	1096	1089	1122	1124	1089	1082	1128	1127	1101	1106	1128	1099	1102	1117	1116
				1105	1121	1101	1113	1110	1107	1112	1107	1119	1105	1099	1110	1115	1101	1115	1100
				1106	1118	1118	1101	1113	1115	1101	1103	1115	1107	1115	1114	1105	1100	1113	1097
				1106	1107	1127	1097	1125	1113	1117	1123	1120	1106	1122	1099	1113	1117	1112	1118
				1102	1124	1132	1122	1091	1138	1133	1137	1105	1131	1094	1129	1095	1131	1106	1091
				1110	1126	1085	1147	1078	1104	1082	1117	1100	1076	1129	1099	1131	1099	1111	1086
				1085	1108	1130	1106	1107	1115	1106	1113	1118	1092	1122	1103	1118	1106	1122	1119
				1087	1106	1106	1098	1121	1112	1106	1120	1110	1137	1115	1094	1114	1124	1114	1085
				1115	1108	1122	1130	1101	1105	1104	1103	1091	1122	1095	1130	1092	1124	1119	1113
				1106	1113	1107	1100	1111	1091	1112	1117	1107	1120	1101	1096	1110	1114	1105	1116
				1106	1112	1102	1109	1109	1095	1113	1114	1124	1132	1092	1090	1122	1127	1091	1110
				1101	1111	1103	1113	1097	1090	1098	1104	1110	1102	1117	1110	1109	1104	1104	1111
				1096	1108	1116	1127	1097	1095	1110	1129	1115	1124	1106	1104	1106	1101	1115	1080
				1090	1091	1117	1092	1127	1125	1094	1123	1129	1127	1110	1106	1113	1106	1114	1101
				1102	1111	1108	1109	1098	1096	1117	1120	1123	1122	1103	1089	1124	1110	1096	1099
				1103	1110	1121	1094	1112	1116	1115	1108	1096	1131	1091	1094	1132	1093	1108	1097
				1108	1111	1107	1121	1119	1121	1102	1117	1117	1108	1116	1103	1110	1122	1094	1108
				1106	1099	1118	1114	1125	1115	1092	1113	1100	1105	1113	1120	1100	1112	1106	1124
				1088	1113	1122	1103	1107	1112	1122	1099	1111	1105	1116	1120	1103	1117	1110	1110
				1107	1107	1094	1122	1096	1107	1110	1110	1098	1110	1103	1101	1110	1105	1117	1090
				1106	1121	1109	1111	1107	1131	1116	1119	1110	1120	1106	1108	1112	1096	1115	1108
				1093	1108	1101	1123	1093	1092	1119	1131	1129	1087	1131	1087	1121	1130	1097	1103
				1109	1120	1096	1125	1095	1115	1124	1085	1099	1099	1115	1096	1103	1127	1102	1103
				1099	1131	1095	1101	1095	1117	1096	1105	1099	1105	1099	1110	1106	1105	1100	1096
				1084	1098	1113	1108	1113	1108	1107	1119	1117	1128	1109	1131	1114	1108	1115	1115
				1094	1120	1096	1120	1103	1115	1111	1122	1111	1121	1115	1116	1124	1121	1099	1112
				1103	1104	1105	1108	1121	1096	1113	1112	1125	1104	1118	1103	1103	1122	1101	1125
				1094	1109	1113	1115	1120	1104	1098	1129	1101	1120	1093	1118	1101	1121	1105	1101
				1102	1117	1089	1124	1099	1110	1129	1114	1108	1106	1111	1113	1121	1099	1096	1109
				1101	1127	1103	1113	1095	1103	1109	1104	1113	1129	1113	1127	1105	1096	1131	1132
				1118	1089	1115	1099	1117	1080	1089	1089	1101	1120	1100	1099	1110	1115	1095	1115
				1117	1109	1129	1103	1112	1107	1124	1099	1105	1108	1109	1119	1103	1122	1121	1108
				1117	1131	1119	1091	1138	1089	1082	1102	1110	1104	1106	1124	1132	1112	1085	1109
				1110	1101	1117	1110	1127	1110	1103	1099	1118	1123	1127	1089	1124	1093	1118	1103
				1119	1109	1087	1096	1117	1093	1119	1111	1116	1103	1097	1117	1125	1103	1113	1112
				240 240 240>;

			PS_Config_Lmt_FW_CC_P = <
				112	125	124	122	121	120	119	65535	65535	125	122	122	122	124	124	110
				126	115	112	110	110	110	110	110	115	114	111	110	111	112	112	115
				135	112	110	109	107	107	107	107	112	112	110	107	110	110	110	115
				122	112	111	110	110	109	109	109	114	112	110	110	111	111	112	117
				119	112	111	110	109	107	107	107	112	111	110	110	110	111	112	115
				120	114	112	111	110	110	110	110	114	112	111	110	112	112	114	116
				120	111	110	109	107	107	107	107	111	111	110	109	110	111	111	116
				120	112	111	110	110	109	110	109	112	112	110	110	111	112	112	119
				117	112	111	110	109	107	109	107	112	111	110	110	110	111	112	115
				119	112	112	111	110	110	110	110	115	112	112	111	112	112	114	115
				119	110	110	109	107	106	107	107	111	110	109	109	110	110	111	116
				120	111	110	110	107	107	107	107	111	110	110	109	110	110	112	120
				116	111	110	110	107	107	107	109	110	110	110	110	110	112	112	116
				117	112	112	111	110	110	110	111	112	112	112	112	112	114	115	119
				116	110	110	107	107	107	107	110	110	110	110	110	110	111	112	117
				119	112	111	110	109	110	110	111	111	111	110	110	111	112	112	119
				115	111	110	110	107	107	109	110	112	110	110	110	111	112	112	115
				117	112	112	111	109	109	110	111	112	111	110	110	111	112	114	117
				115	111	110	109	106	107	107	109	109	109	107	107	109	110	111	117
				117	112	110	110	107	107	109	110	112	110	110	110	110	111	112	120
				115	111	110	109	109	109	109	109	111	110	109	110	110	111	112	117
				116	112	112	110	110	110	110	110	112	111	110	110	112	112	114	120
				116	110	110	107	107	107	107	109	110	110	109	109	110	110	112	119
				117	111	111	110	109	109	110	111	111	110	109	110	111	112	112	122
				115	111	110	109	107	109	109	110	110	110	109	109	111	111	112	120
				116	114	112	111	110	111	112	112	112	112	111	112	112	115	115	121
				115	111	110	109	107	109	110	111	109	110	109	110	110	111	112	121
				119	112	112	110	110	110	111	112	110	111	110	111	112	112	115	122
				115	112	111	110	109	110	111	112	110	110	110	110	112	112	114	121
				117	114	114	111	110	111	112	114	111	112	111	112	112	115	116	122
				116	111	110	109	107	109	109	111	110	110	109	110	111	112	115	122
				117	114	112	111	110	111	112	114	110	111	110	112	112	114	115	125
				115	112	110	110	109	110	111	112	110	110	110	110	112	112	115	122
				117	114	112	112	110	111	114	115	111	111	111	112	114	115	117	140
				115	112	110	110	109	109	114	112	109	109	109	110	111	112	115	115
				112	124	122	122	121	122	126	126	124	122	124	124	125	126	128	120
				314 314 314>;

			PS_Config_Lmt_FW_CC_N = <
				69	76	76	75	74	73	72	(-65535)	(-65535)	76	75	75	75	76	76	67
				77	70	69	67	67	67	67	67	70	69	68	67	68	69	69	70
				82	69	67	66	66	66	66	66	69	69	67	66	67	67	67	70
				75	69	68	67	67	66	66	66	69	69	67	67	68	68	69	72
				72	69	68	67	66	66	66	66	69	68	67	67	67	68	69	70
				73	69	69	68	67	67	67	67	69	69	68	67	69	69	69	71
				73	68	67	66	66	66	66	66	68	68	67	66	67	68	68	71
				73	69	68	67	67	66	67	66	69	69	67	67	68	69	69	72
				72	69	68	67	66	66	66	66	69	68	67	67	67	68	69	70
				72	69	69	68	67	67	67	67	70	69	69	68	69	69	69	70
				72	67	67	66	66	65	66	66	68	67	66	66	67	67	68	71
				73	68	67	67	66	66	66	66	68	67	67	66	67	67	69	73
				71	68	67	67	66	66	66	66	67	67	67	67	67	69	69	71
				72	69	69	68	67	67	67	68	69	69	69	69	69	69	70	72
				71	67	67	66	66	66	66	67	67	67	67	67	67	68	69	72
				72	69	68	67	66	67	67	68	68	68	67	67	68	69	69	72
				70	68	67	67	66	66	66	67	69	67	67	67	68	69	69	70
				72	69	69	68	66	66	67	68	69	68	67	67	68	69	69	72
				70	68	67	66	65	66	66	66	66	66	66	66	66	67	68	72
				72	69	67	67	66	66	66	67	69	67	67	67	67	68	69	73
				70	68	67	66	66	66	66	66	68	67	66	67	67	68	69	72
				71	69	69	67	67	67	67	67	69	68	67	67	69	69	69	73
				71	67	67	66	66	66	66	66	67	67	66	66	67	67	69	72
				72	68	68	67	66	66	67	68	68	67	66	67	68	69	69	75
				70	68	67	66	66	66	66	67	67	67	66	66	68	68	69	73
				71	69	69	68	67	68	69	69	69	69	68	69	69	70	70	74
				70	68	67	66	66	66	67	68	66	67	66	67	67	68	69	74
				72	69	69	67	67	67	68	69	67	68	67	68	69	69	70	75
				70	69	68	67	66	67	68	69	67	67	67	67	69	69	69	74
				72	69	69	68	67	68	69	69	68	69	68	69	69	70	71	75
				71	68	67	66	66	66	66	68	67	67	66	67	68	69	70	75
				72	69	69	68	67	68	69	69	67	68	67	69	69	69	70	76
				70	69	67	67	66	67	68	69	67	67	67	67	69	69	70	75
				72	69	69	69	67	68	69	70	68	68	68	69	69	70	72	85
				70	69	67	67	66	66	69	69	66	66	66	67	68	69	70	70
				69	76	75	75	74	75	77	77	76	75	76	76	76	77	79	73
				0 0 0>;

			PS_Config_Lmt_FW_Diff_P = <
				50	50	50	50	50	50	50	65535	65535	50	50	50	50	50	50	50
				50	50	50	50	50	50	50	50	50	50	50	50	50	50	50	50
				50	50	50	50	50	50	50	50	50	50	50	50	50	50	50	50
				50	50	50	50	50	50	50	50	50	50	50	50	50	50	50	50
				50	50	50	50	50	50	50	50	50	50	50	50	50	50	50	50
				50	50	50	50	50	50	50	50	50	50	50	50	50	50	50	50
				50	50	50	50	50	50	50	50	50	50	50	50	50	50	50	50
				50	50	50	50	50	50	50	50	50	50	50	50	50	50	50	50
				50	50	50	50	50	50	50	50	50	50	50	50	50	50	50	50
				50	50	50	50	50	50	50	50	50	50	50	50	50	50	50	50
				50	50	50	50	50	50	50	50	50	50	50	50	50	50	50	50
				50	50	50	50	50	50	50	50	50	50	50	50	50	50	50	50
				50	50	50	50	50	50	50	50	50	50	50	50	50	50	50	50
				50	50	50	50	50	50	50	50	50	50	50	50	50	50	50	50
				50	50	50	50	50	50	50	50	50	50	50	50	50	50	50	50
				50	50	50	50	50	50	50	50	50	50	50	50	50	50	50	50
				50	50	50	50	50	50	50	50	50	50	50	50	50	50	50	50
				50	50	50	50	50	50	50	50	50	50	50	50	50	50	50	50
				50	50	50	50	50	50	50	50	50	50	50	50	50	50	50	50
				50	50	50	50	50	50	50	50	50	50	50	50	50	50	50	50
				50	50	50	50	50	50	50	50	50	50	50	50	50	50	50	50
				50	50	50	50	50	50	50	50	50	50	50	50	50	50	50	50
				50	50	50	50	50	50	50	50	50	50	50	50	50	50	50	50
				50	50	50	50	50	50	50	50	50	50	50	50	50	50	50	50
				50	50	50	50	50	50	50	50	50	50	50	50	50	50	50	50
				50	50	50	50	50	50	50	50	50	50	50	50	50	50	50	50
				50	50	50	50	50	50	50	50	50	50	50	50	50	50	50	50
				50	50	50	50	50	50	50	50	50	50	50	50	50	50	50	50
				50	50	50	50	50	50	50	50	50	50	50	50	50	50	50	50
				50	50	50	50	50	50	50	50	50	50	50	50	50	50	50	50
				50	50	50	50	50	50	50	50	50	50	50	50	50	50	50	50
				50	50	50	50	50	50	50	50	50	50	50	50	50	50	50	50
				50	50	50	50	50	50	50	50	50	50	50	50	50	50	50	50
				50	50	50	50	50	50	50	50	50	50	50	50	50	50	50	50
				50	50	50	50	50	50	50	50	50	50	50	50	50	50	50	50
				50	50	50	50	50	50	50	50	50	50	50	50	50	50	50	50
				75 75 75>;

			PS_Config_Lmt_FW_Diff_N = <
				(-50)	(-50)	(-50)	(-50)	(-50)	(-50)	(-50)	(-65535)	(-65535)	(-50)	(-50)	(-50)	(-50)	(-50)	(-50)	(-50)
				(-50)	(-50)	(-50)	(-50)	(-50)	(-50)	(-50)	(-50)	(-50)	(-50)	(-50)	(-50)	(-50)	(-50)	(-50)	(-50)
				(-50)	(-50)	(-50)	(-50)	(-50)	(-50)	(-50)	(-50)	(-50)	(-50)	(-50)	(-50)	(-50)	(-50)	(-50)	(-50)
				(-50)	(-50)	(-50)	(-50)	(-50)	(-50)	(-50)	(-50)	(-50)	(-50)	(-50)	(-50)	(-50)	(-50)	(-50)	(-50)
				(-50)	(-50)	(-50)	(-50)	(-50)	(-50)	(-50)	(-50)	(-50)	(-50)	(-50)	(-50)	(-50)	(-50)	(-50)	(-50)
				(-50)	(-50)	(-50)	(-50)	(-50)	(-50)	(-50)	(-50)	(-50)	(-50)	(-50)	(-50)	(-50)	(-50)	(-50)	(-50)
				(-50)	(-50)	(-50)	(-50)	(-50)	(-50)	(-50)	(-50)	(-50)	(-50)	(-50)	(-50)	(-50)	(-50)	(-50)	(-50)
				(-50)	(-50)	(-50)	(-50)	(-50)	(-50)	(-50)	(-50)	(-50)	(-50)	(-50)	(-50)	(-50)	(-50)	(-50)	(-50)
				(-50)	(-50)	(-50)	(-50)	(-50)	(-50)	(-50)	(-50)	(-50)	(-50)	(-50)	(-50)	(-50)	(-50)	(-50)	(-50)
				(-50)	(-50)	(-50)	(-50)	(-50)	(-50)	(-50)	(-50)	(-50)	(-50)	(-50)	(-50)	(-50)	(-50)	(-50)	(-50)
				(-50)	(-50)	(-50)	(-50)	(-50)	(-50)	(-50)	(-50)	(-50)	(-50)	(-50)	(-50)	(-50)	(-50)	(-50)	(-50)
				(-50)	(-50)	(-50)	(-50)	(-50)	(-50)	(-50)	(-50)	(-50)	(-50)	(-50)	(-50)	(-50)	(-50)	(-50)	(-50)
				(-50)	(-50)	(-50)	(-50)	(-50)	(-50)	(-50)	(-50)	(-50)	(-50)	(-50)	(-50)	(-50)	(-50)	(-50)	(-50)
				(-50)	(-50)	(-50)	(-50)	(-50)	(-50)	(-50)	(-50)	(-50)	(-50)	(-50)	(-50)	(-50)	(-50)	(-50)	(-50)
				(-50)	(-50)	(-50)	(-50)	(-50)	(-50)	(-50)	(-50)	(-50)	(-50)	(-50)	(-50)	(-50)	(-50)	(-50)	(-50)
				(-50)	(-50)	(-50)	(-50)	(-50)	(-50)	(-50)	(-50)	(-50)	(-50)	(-50)	(-50)	(-50)	(-50)	(-50)	(-50)
				(-50)	(-50)	(-50)	(-50)	(-50)	(-50)	(-50)	(-50)	(-50)	(-50)	(-50)	(-50)	(-50)	(-50)	(-50)	(-50)
				(-50)	(-50)	(-50)	(-50)	(-50)	(-50)	(-50)	(-50)	(-50)	(-50)	(-50)	(-50)	(-50)	(-50)	(-50)	(-50)
				(-50)	(-50)	(-50)	(-50)	(-50)	(-50)	(-50)	(-50)	(-50)	(-50)	(-50)	(-50)	(-50)	(-50)	(-50)	(-50)
				(-50)	(-50)	(-50)	(-50)	(-50)	(-50)	(-50)	(-50)	(-50)	(-50)	(-50)	(-50)	(-50)	(-50)	(-50)	(-50)
				(-50)	(-50)	(-50)	(-50)	(-50)	(-50)	(-50)	(-50)	(-50)	(-50)	(-50)	(-50)	(-50)	(-50)	(-50)	(-50)
				(-50)	(-50)	(-50)	(-50)	(-50)	(-50)	(-50)	(-50)	(-50)	(-50)	(-50)	(-50)	(-50)	(-50)	(-50)	(-50)
				(-50)	(-50)	(-50)	(-50)	(-50)	(-50)	(-50)	(-50)	(-50)	(-50)	(-50)	(-50)	(-50)	(-50)	(-50)	(-50)
				(-50)	(-50)	(-50)	(-50)	(-50)	(-50)	(-50)	(-50)	(-50)	(-50)	(-50)	(-50)	(-50)	(-50)	(-50)	(-50)
				(-50)	(-50)	(-50)	(-50)	(-50)	(-50)	(-50)	(-50)	(-50)	(-50)	(-50)	(-50)	(-50)	(-50)	(-50)	(-50)
				(-50)	(-50)	(-50)	(-50)	(-50)	(-50)	(-50)	(-50)	(-50)	(-50)	(-50)	(-50)	(-50)	(-50)	(-50)	(-50)
				(-50)	(-50)	(-50)	(-50)	(-50)	(-50)	(-50)	(-50)	(-50)	(-50)	(-50)	(-50)	(-50)	(-50)	(-50)	(-50)
				(-50)	(-50)	(-50)	(-50)	(-50)	(-50)	(-50)	(-50)	(-50)	(-50)	(-50)	(-50)	(-50)	(-50)	(-50)	(-50)
				(-50)	(-50)	(-50)	(-50)	(-50)	(-50)	(-50)	(-50)	(-50)	(-50)	(-50)	(-50)	(-50)	(-50)	(-50)	(-50)
				(-50)	(-50)	(-50)	(-50)	(-50)	(-50)	(-50)	(-50)	(-50)	(-50)	(-50)	(-50)	(-50)	(-50)	(-50)	(-50)
				(-50)	(-50)	(-50)	(-50)	(-50)	(-50)	(-50)	(-50)	(-50)	(-50)	(-50)	(-50)	(-50)	(-50)	(-50)	(-50)
				(-50)	(-50)	(-50)	(-50)	(-50)	(-50)	(-50)	(-50)	(-50)	(-50)	(-50)	(-50)	(-50)	(-50)	(-50)	(-50)
				(-50)	(-50)	(-50)	(-50)	(-50)	(-50)	(-50)	(-50)	(-50)	(-50)	(-50)	(-50)	(-50)	(-50)	(-50)	(-50)
				(-50)	(-50)	(-50)	(-50)	(-50)	(-50)	(-50)	(-50)	(-50)	(-50)	(-50)	(-50)	(-50)	(-50)	(-50)	(-50)
				(-50)	(-50)	(-50)	(-50)	(-50)	(-50)	(-50)	(-50)	(-50)	(-50)	(-50)	(-50)	(-50)	(-50)	(-50)	(-50)
				(-50)	(-50)	(-50)	(-50)	(-50)	(-50)	(-50)	(-50)	(-50)	(-50)	(-50)	(-50)	(-50)	(-50)	(-50)	(-50)
				(-75) (-75) (-75)>;

			PS_Config_Diff_Test_Frame = <50>;
		};

		/*for Xiaomi J19 672A BOE6.53" DJN module*/
		novatek-mp-criteria-5939@0 {
			#address-cells = <1>;
			#size-cells = <0>;
			compatible = "novatek-mp-criteria-5939";

			/* MP Config */
			IC_X_CFG_SIZE = <18>;
			IC_Y_CFG_SIZE = <36>;
			IC_KEY_CFG_SIZE = <4>;
			X_Channel = <18>;
			Y_Channel = <36>;
			AIN_X = <0 1 2 3 4 5 6 7 8 9 10 11 12 13 14 15 16 17>;
			AIN_Y = <0 1 2 3 4 5 6 7 8 9 10 11 12 13 14 15 16 17
						18 19 20 21 22 23 24 25 26 27 28 29 30 31 32 33 34 35>;
			AIN_KEY = <0 1 2 0xFF>;

			/* MP Criteria */
			PS_Config_Lmt_Short_Rawdata_P = <
				14008 14008 14008 14008 14008 14008 14008 14008 14008 14008 14008 14008 14008 14008 14008 14008 14008 14008
				14008 14008 14008 14008 14008 14008 14008 14008 14008 14008 14008 14008 14008 14008 14008 14008 14008 14008
				14008 14008 14008 14008 14008 14008 14008 14008 14008 14008 14008 14008 14008 14008 14008 14008 14008 14008
				14008 14008 14008 14008 14008 14008 14008 14008 14008 14008 14008 14008 14008 14008 14008 14008 14008 14008
				14008 14008 14008 14008 14008 14008 14008 14008 14008 14008 14008 14008 14008 14008 14008 14008 14008 14008
				14008 14008 14008 14008 14008 14008 14008 14008 14008 14008 14008 14008 14008 14008 14008 14008 14008 14008
				14008 14008 14008 14008 14008 14008 14008 14008 14008 14008 14008 14008 14008 14008 14008 14008 14008 14008
				14008 14008 14008 14008 14008 14008 14008 14008 14008 14008 14008 14008 14008 14008 14008 14008 14008 14008
				14008 14008 14008 14008 14008 14008 14008 14008 14008 14008 14008 14008 14008 14008 14008 14008 14008 14008
				14008 14008 14008 14008 14008 14008 14008 14008 14008 14008 14008 14008 14008 14008 14008 14008 14008 14008
				14008 14008 14008 14008 14008 14008 14008 14008 14008 14008 14008 14008 14008 14008 14008 14008 14008 14008
				14008 14008 14008 14008 14008 14008 14008 14008 14008 14008 14008 14008 14008 14008 14008 14008 14008 14008
				14008 14008 14008 14008 14008 14008 14008 14008 14008 14008 14008 14008 14008 14008 14008 14008 14008 14008
				14008 14008 14008 14008 14008 14008 14008 14008 14008 14008 14008 14008 14008 14008 14008 14008 14008 14008
				14008 14008 14008 14008 14008 14008 14008 14008 14008 14008 14008 14008 14008 14008 14008 14008 14008 14008
				14008 14008 14008 14008 14008 14008 14008 14008 14008 14008 14008 14008 14008 14008 14008 14008 14008 14008
				14008 14008 14008 14008 14008 14008 14008 14008 14008 14008 14008 14008 14008 14008 14008 14008 14008 14008
				14008 14008 14008 14008 14008 14008 14008 14008 14008 14008 14008 14008 14008 14008 14008 14008 14008 14008
				14008 14008 14008 14008 14008 14008 14008 14008 14008 14008 14008 14008 14008 14008 14008 14008 14008 14008
				14008 14008 14008 14008 14008 14008 14008 14008 14008 14008 14008 14008 14008 14008 14008 14008 14008 14008
				14008 14008 14008 14008 14008 14008 14008 14008 14008 14008 14008 14008 14008 14008 14008 14008 14008 14008
				14008 14008 14008 14008 14008 14008 14008 14008 14008 14008 14008 14008 14008 14008 14008 14008 14008 14008
				14008 14008 14008 14008 14008 14008 14008 14008 14008 14008 14008 14008 14008 14008 14008 14008 14008 14008
				14008 14008 14008 14008 14008 14008 14008 14008 14008 14008 14008 14008 14008 14008 14008 14008 14008 14008
				14008 14008 14008 14008 14008 14008 14008 14008 14008 14008 14008 14008 14008 14008 14008 14008 14008 14008
				14008 14008 14008 14008 14008 14008 14008 14008 14008 14008 14008 14008 14008 14008 14008 14008 14008 14008
				14008 14008 14008 14008 14008 14008 14008 14008 14008 14008 14008 14008 14008 14008 14008 14008 14008 14008
				14008 14008 14008 14008 14008 14008 14008 14008 14008 14008 14008 14008 14008 14008 14008 14008 14008 14008
				14008 14008 14008 14008 14008 14008 14008 14008 14008 14008 14008 14008 14008 14008 14008 14008 14008 14008
				14008 14008 14008 14008 14008 14008 14008 14008 14008 14008 14008 14008 14008 14008 14008 14008 14008 14008
				14008 14008 14008 14008 14008 14008 14008 14008 14008 14008 14008 14008 14008 14008 14008 14008 14008 14008
				14008 14008 14008 14008 14008 14008 14008 14008 14008 14008 14008 14008 14008 14008 14008 14008 14008 14008
				14008 14008 14008 14008 14008 14008 14008 14008 14008 14008 14008 14008 14008 14008 14008 14008 14008 14008
				14008 14008 14008 14008 14008 14008 14008 14008 14008 14008 14008 14008 14008 14008 14008 14008 14008 14008
				14008 14008 14008 14008 14008 14008 14008 14008 14008 14008 14008 14008 14008 14008 14008 14008 14008 14008
				14008 14008 14008 14008 14008 14008 14008 14008 14008 14008 14008 14008 14008 14008 14008 14008 14008 14008
				14008 14008 14008>;

			PS_Config_Lmt_Short_Rawdata_N = <
				10000 10000 10000 10000 10000 10000 10000 10000 10000 10000 10000 10000 10000 10000 10000 10000 10000 10000
				10000 10000 10000 10000 10000 10000 10000 10000 10000 10000 10000 10000 10000 10000 10000 10000 10000 10000
				10000 10000 10000 10000 10000 10000 10000 10000 10000 10000 10000 10000 10000 10000 10000 10000 10000 10000
				10000 10000 10000 10000 10000 10000 10000 10000 10000 10000 10000 10000 10000 10000 10000 10000 10000 10000
				10000 10000 10000 10000 10000 10000 10000 10000 10000 10000 10000 10000 10000 10000 10000 10000 10000 10000
				10000 10000 10000 10000 10000 10000 10000 10000 10000 10000 10000 10000 10000 10000 10000 10000 10000 10000
				10000 10000 10000 10000 10000 10000 10000 10000 10000 10000 10000 10000 10000 10000 10000 10000 10000 10000
				10000 10000 10000 10000 10000 10000 10000 10000 10000 10000 10000 10000 10000 10000 10000 10000 10000 10000
				10000 10000 10000 10000 10000 10000 10000 10000 10000 10000 10000 10000 10000 10000 10000 10000 10000 10000
				10000 10000 10000 10000 10000 10000 10000 10000 10000 10000 10000 10000 10000 10000 10000 10000 10000 10000
				10000 10000 10000 10000 10000 10000 10000 10000 10000 10000 10000 10000 10000 10000 10000 10000 10000 10000
				10000 10000 10000 10000 10000 10000 10000 10000 10000 10000 10000 10000 10000 10000 10000 10000 10000 10000
				10000 10000 10000 10000 10000 10000 10000 10000 10000 10000 10000 10000 10000 10000 10000 10000 10000 10000
				10000 10000 10000 10000 10000 10000 10000 10000 10000 10000 10000 10000 10000 10000 10000 10000 10000 10000
				10000 10000 10000 10000 10000 10000 10000 10000 10000 10000 10000 10000 10000 10000 10000 10000 10000 10000
				10000 10000 10000 10000 10000 10000 10000 10000 10000 10000 10000 10000 10000 10000 10000 10000 10000 10000
				10000 10000 10000 10000 10000 10000 10000 10000 10000 10000 10000 10000 10000 10000 10000 10000 10000 10000
				10000 10000 10000 10000 10000 10000 10000 10000 10000 10000 10000 10000 10000 10000 10000 10000 10000 10000
				10000 10000 10000 10000 10000 10000 10000 10000 10000 10000 10000 10000 10000 10000 10000 10000 10000 10000
				10000 10000 10000 10000 10000 10000 10000 10000 10000 10000 10000 10000 10000 10000 10000 10000 10000 10000
				10000 10000 10000 10000 10000 10000 10000 10000 10000 10000 10000 10000 10000 10000 10000 10000 10000 10000
				10000 10000 10000 10000 10000 10000 10000 10000 10000 10000 10000 10000 10000 10000 10000 10000 10000 10000
				10000 10000 10000 10000 10000 10000 10000 10000 10000 10000 10000 10000 10000 10000 10000 10000 10000 10000
				10000 10000 10000 10000 10000 10000 10000 10000 10000 10000 10000 10000 10000 10000 10000 10000 10000 10000
				10000 10000 10000 10000 10000 10000 10000 10000 10000 10000 10000 10000 10000 10000 10000 10000 10000 10000
				10000 10000 10000 10000 10000 10000 10000 10000 10000 10000 10000 10000 10000 10000 10000 10000 10000 10000
				10000 10000 10000 10000 10000 10000 10000 10000 10000 10000 10000 10000 10000 10000 10000 10000 10000 10000
				10000 10000 10000 10000 10000 10000 10000 10000 10000 10000 10000 10000 10000 10000 10000 10000 10000 10000
				10000 10000 10000 10000 10000 10000 10000 10000 10000 10000 10000 10000 10000 10000 10000 10000 10000 10000
				10000 10000 10000 10000 10000 10000 10000 10000 10000 10000 10000 10000 10000 10000 10000 10000 10000 10000
				10000 10000 10000 10000 10000 10000 10000 10000 10000 10000 10000 10000 10000 10000 10000 10000 10000 10000
				10000 10000 10000 10000 10000 10000 10000 10000 10000 10000 10000 10000 10000 10000 10000 10000 10000 10000
				10000 10000 10000 10000 10000 10000 10000 10000 10000 10000 10000 10000 10000 10000 10000 10000 10000 10000
				10000 10000 10000 10000 10000 10000 10000 10000 10000 10000 10000 10000 10000 10000 10000 10000 10000 10000
				10000 10000 10000 10000 10000 10000 10000 10000 10000 10000 10000 10000 10000 10000 10000 10000 10000 10000
				10000 10000 10000 10000 10000 10000 10000 10000 10000 10000 10000 10000 10000 10000 10000 10000 10000 10000
				10000 10000 10000>;

			PS_Config_Lmt_Open_Rawdata_P = <
				5120 5120 5120 5120 5120 5120 5120 5120 5120 5120 5120 5120 5120 5120 5120 5120 5120 5120
				5120 5120 5120 5120 5120 5120 5120 5120 5120 5120 5120 5120 5120 5120 5120 5120 5120 5120
				5120 5120 5120 5120 5120 5120 5120 5120 5120 5120 5120 5120 5120 5120 5120 5120 5120 5120
				5120 5120 5120 5120 5120 5120 5120 5120 5120 5120 5120 5120 5120 5120 5120 5120 5120 5120
				5120 5120 5120 5120 5120 5120 5120 5120 5120 5120 5120 5120 5120 5120 5120 5120 5120 5120
				5120 5120 5120 5120 5120 5120 5120 5120 5120 5120 5120 5120 5120 5120 5120 5120 5120 5120
				5120 5120 5120 5120 5120 5120 5120 5120 5120 5120 5120 5120 5120 5120 5120 5120 5120 5120
				5120 5120 5120 5120 5120 5120 5120 5120 5120 5120 5120 5120 5120 5120 5120 5120 5120 5120
				5120 5120 5120 5120 5120 5120 5120 5120 5120 5120 5120 5120 5120 5120 5120 5120 5120 5120
				5120 5120 5120 5120 5120 5120 5120 5120 5120 5120 5120 5120 5120 5120 5120 5120 5120 5120
				5120 5120 5120 5120 5120 5120 5120 5120 5120 5120 5120 5120 5120 5120 5120 5120 5120 5120
				5120 5120 5120 5120 5120 5120 5120 5120 5120 5120 5120 5120 5120 5120 5120 5120 5120 5120
				5120 5120 5120 5120 5120 5120 5120 5120 5120 5120 5120 5120 5120 5120 5120 5120 5120 5120
				5120 5120 5120 5120 5120 5120 5120 5120 5120 5120 5120 5120 5120 5120 5120 5120 5120 5120
				5120 5120 5120 5120 5120 5120 5120 5120 5120 5120 5120 5120 5120 5120 5120 5120 5120 5120
				5120 5120 5120 5120 5120 5120 5120 5120 5120 5120 5120 5120 5120 5120 5120 5120 5120 5120
				5120 5120 5120 5120 5120 5120 5120 5120 5120 5120 5120 5120 5120 5120 5120 5120 5120 5120
				5120 5120 5120 5120 5120 5120 5120 5120 5120 5120 5120 5120 5120 5120 5120 5120 5120 5120
				5120 5120 5120 5120 5120 5120 5120 5120 5120 5120 5120 5120 5120 5120 5120 5120 5120 5120
				5120 5120 5120 5120 5120 5120 5120 5120 5120 5120 5120 5120 5120 5120 5120 5120 5120 5120
				5120 5120 5120 5120 5120 5120 5120 5120 5120 5120 5120 5120 5120 5120 5120 5120 5120 5120
				5120 5120 5120 5120 5120 5120 5120 5120 5120 5120 5120 5120 5120 5120 5120 5120 5120 5120
				5120 5120 5120 5120 5120 5120 5120 5120 5120 5120 5120 5120 5120 5120 5120 5120 5120 5120
				5120 5120 5120 5120 5120 5120 5120 5120 5120 5120 5120 5120 5120 5120 5120 5120 5120 5120
				5120 5120 5120 5120 5120 5120 5120 5120 5120 5120 5120 5120 5120 5120 5120 5120 5120 5120
				5120 5120 5120 5120 5120 5120 5120 5120 5120 5120 5120 5120 5120 5120 5120 5120 5120 5120
				5120 5120 5120 5120 5120 5120 5120 5120 5120 5120 5120 5120 5120 5120 5120 5120 5120 5120
				5120 5120 5120 5120 5120 5120 5120 5120 5120 5120 5120 5120 5120 5120 5120 5120 5120 5120
				5120 5120 5120 5120 5120 5120 5120 5120 5120 5120 5120 5120 5120 5120 5120 5120 5120 5120
				5120 5120 5120 5120 5120 5120 5120 5120 5120 5120 5120 5120 5120 5120 5120 5120 5120 5120
				5120 5120 5120 5120 5120 5120 5120 5120 5120 5120 5120 5120 5120 5120 5120 5120 5120 5120
				5120 5120 5120 5120 5120 5120 5120 5120 5120 5120 5120 5120 5120 5120 5120 5120 5120 5120
				5120 5120 5120 5120 5120 5120 5120 5120 5120 5120 5120 5120 5120 5120 5120 5120 5120 5120
				5120 5120 5120 5120 5120 5120 5120 5120 5120 5120 5120 5120 5120 5120 5120 5120 5120 5120
				5120 5120 5120 5120 5120 5120 5120 5120 5120 5120 5120 5120 5120 5120 5120 5120 5120 5120
				5120 5120 5120 5120 5120 5120 5120 5120 5120 5120 5120 5120 5120 5120 5120 5120 5120 5120
				5120 5120 5120>;

			PS_Config_Lmt_Open_Rawdata_N = <
				(-511) (-511) (-511) (-511) (-511) (-511) (-511) (-511) (-511) (-511) (-511) (-511) (-511) (-511) (-511) (-511) (-511) (-511)
				(-511) (-511) (-511) (-511) (-511) (-511) (-511) (-511) (-511) (-511) (-511) (-511) (-511) (-511) (-511) (-511) (-511) (-511)
				(-511) (-511) (-511) (-511) (-511) (-511) (-511) (-511) (-511) (-511) (-511) (-511) (-511) (-511) (-511) (-511) (-511) (-511)
				(-511) (-511) (-511) (-511) (-511) (-511) (-511) (-511) (-511) (-511) (-511) (-511) (-511) (-511) (-511) (-511) (-511) (-511)
				(-511) (-511) (-511) (-511) (-511) (-511) (-511) (-511) (-511) (-511) (-511) (-511) (-511) (-511) (-511) (-511) (-511) (-511)
				(-511) (-511) (-511) (-511) (-511) (-511) (-511) (-511) (-511) (-511) (-511) (-511) (-511) (-511) (-511) (-511) (-511) (-511)
				(-511) (-511) (-511) (-511) (-511) (-511) (-511) (-511) (-511) (-511) (-511) (-511) (-511) (-511) (-511) (-511) (-511) (-511)
				(-511) (-511) (-511) (-511) (-511) (-511) (-511) (-511) (-511) (-511) (-511) (-511) (-511) (-511) (-511) (-511) (-511) (-511)
				(-511) (-511) (-511) (-511) (-511) (-511) (-511) (-511) (-511) (-511) (-511) (-511) (-511) (-511) (-511) (-511) (-511) (-511)
				(-511) (-511) (-511) (-511) (-511) (-511) (-511) (-511) (-511) (-511) (-511) (-511) (-511) (-511) (-511) (-511) (-511) (-511)
				(-511) (-511) (-511) (-511) (-511) (-511) (-511) (-511) (-511) (-511) (-511) (-511) (-511) (-511) (-511) (-511) (-511) (-511)
				(-511) (-511) (-511) (-511) (-511) (-511) (-511) (-511) (-511) (-511) (-511) (-511) (-511) (-511) (-511) (-511) (-511) (-511)
				(-511) (-511) (-511) (-511) (-511) (-511) (-511) (-511) (-511) (-511) (-511) (-511) (-511) (-511) (-511) (-511) (-511) (-511)
				(-511) (-511) (-511) (-511) (-511) (-511) (-511) (-511) (-511) (-511) (-511) (-511) (-511) (-511) (-511) (-511) (-511) (-511)
				(-511) (-511) (-511) (-511) (-511) (-511) (-511) (-511) (-511) (-511) (-511) (-511) (-511) (-511) (-511) (-511) (-511) (-511)
				(-511) (-511) (-511) (-511) (-511) (-511) (-511) (-511) (-511) (-511) (-511) (-511) (-511) (-511) (-511) (-511) (-511) (-511)
				(-511) (-511) (-511) (-511) (-511) (-511) (-511) (-511) (-511) (-511) (-511) (-511) (-511) (-511) (-511) (-511) (-511) (-511)
				(-511) (-511) (-511) (-511) (-511) (-511) (-511) (-511) (-511) (-511) (-511) (-511) (-511) (-511) (-511) (-511) (-511) (-511)
				(-511) (-511) (-511) (-511) (-511) (-511) (-511) (-511) (-511) (-511) (-511) (-511) (-511) (-511) (-511) (-511) (-511) (-511)
				(-511) (-511) (-511) (-511) (-511) (-511) (-511) (-511) (-511) (-511) (-511) (-511) (-511) (-511) (-511) (-511) (-511) (-511)
				(-511) (-511) (-511) (-511) (-511) (-511) (-511) (-511) (-511) (-511) (-511) (-511) (-511) (-511) (-511) (-511) (-511) (-511)
				(-511) (-511) (-511) (-511) (-511) (-511) (-511) (-511) (-511) (-511) (-511) (-511) (-511) (-511) (-511) (-511) (-511) (-511)
				(-511) (-511) (-511) (-511) (-511) (-511) (-511) (-511) (-511) (-511) (-511) (-511) (-511) (-511) (-511) (-511) (-511) (-511)
				(-511) (-511) (-511) (-511) (-511) (-511) (-511) (-511) (-511) (-511) (-511) (-511) (-511) (-511) (-511) (-511) (-511) (-511)
				(-511) (-511) (-511) (-511) (-511) (-511) (-511) (-511) (-511) (-511) (-511) (-511) (-511) (-511) (-511) (-511) (-511) (-511)
				(-511) (-511) (-511) (-511) (-511) (-511) (-511) (-511) (-511) (-511) (-511) (-511) (-511) (-511) (-511) (-511) (-511) (-511)
				(-511) (-511) (-511) (-511) (-511) (-511) (-511) (-511) (-511) (-511) (-511) (-511) (-511) (-511) (-511) (-511) (-511) (-511)
				(-511) (-511) (-511) (-511) (-511) (-511) (-511) (-511) (-511) (-511) (-511) (-511) (-511) (-511) (-511) (-511) (-511) (-511)
				(-511) (-511) (-511) (-511) (-511) (-511) (-511) (-511) (-511) (-511) (-511) (-511) (-511) (-511) (-511) (-511) (-511) (-511)
				(-511) (-511) (-511) (-511) (-511) (-511) (-511) (-511) (-511) (-511) (-511) (-511) (-511) (-511) (-511) (-511) (-511) (-511)
				(-511) (-511) (-511) (-511) (-511) (-511) (-511) (-511) (-511) (-511) (-511) (-511) (-511) (-511) (-511) (-511) (-511) (-511)
				(-511) (-511) (-511) (-511) (-511) (-511) (-511) (-511) (-511) (-511) (-511) (-511) (-511) (-511) (-511) (-511) (-511) (-511)
				(-511) (-511) (-511) (-511) (-511) (-511) (-511) (-511) (-511) (-511) (-511) (-511) (-511) (-511) (-511) (-511) (-511) (-511)
				(-511) (-511) (-511) (-511) (-511) (-511) (-511) (-511) (-511) (-511) (-511) (-511) (-511) (-511) (-511) (-511) (-511) (-511)
				(-511) (-511) (-511) (-511) (-511) (-511) (-511) (-511) (-511) (-511) (-511) (-511) (-511) (-511) (-511) (-511) (-511) (-511)
				(-511) (-511) (-511) (-511) (-511) (-511) (-511) (-511) (-511) (-511) (-511) (-511) (-511) (-511) (-511) (-511) (-511) (-511)
				(-511) (-511) (-511)>;

			PS_Config_Lmt_FW_Rawdata_P = <
				2560 2560 2560 2560 2560 2560 2560 2560 2560 2560 2560 2560 2560 2560 2560 2560 2560 2560
				2560 2560 2560 2560 2560 2560 2560 2560 2560 2560 2560 2560 2560 2560 2560 2560 2560 2560
				2560 2560 2560 2560 2560 2560 2560 2560 2560 2560 2560 2560 2560 2560 2560 2560 2560 2560
				2560 2560 2560 2560 2560 2560 2560 2560 2560 2560 2560 2560 2560 2560 2560 2560 2560 2560
				2560 2560 2560 2560 2560 2560 2560 2560 2560 2560 2560 2560 2560 2560 2560 2560 2560 2560
				2560 2560 2560 2560 2560 2560 2560 2560 2560 2560 2560 2560 2560 2560 2560 2560 2560 2560
				2560 2560 2560 2560 2560 2560 2560 2560 2560 2560 2560 2560 2560 2560 2560 2560 2560 2560
				2560 2560 2560 2560 2560 2560 2560 2560 2560 2560 2560 2560 2560 2560 2560 2560 2560 2560
				2560 2560 2560 2560 2560 2560 2560 2560 2560 2560 2560 2560 2560 2560 2560 2560 2560 2560
				2560 2560 2560 2560 2560 2560 2560 2560 2560 2560 2560 2560 2560 2560 2560 2560 2560 2560
				2560 2560 2560 2560 2560 2560 2560 2560 2560 2560 2560 2560 2560 2560 2560 2560 2560 2560
				2560 2560 2560 2560 2560 2560 2560 2560 2560 2560 2560 2560 2560 2560 2560 2560 2560 2560
				2560 2560 2560 2560 2560 2560 2560 2560 2560 2560 2560 2560 2560 2560 2560 2560 2560 2560
				2560 2560 2560 2560 2560 2560 2560 2560 2560 2560 2560 2560 2560 2560 2560 2560 2560 2560
				2560 2560 2560 2560 2560 2560 2560 2560 2560 2560 2560 2560 2560 2560 2560 2560 2560 2560
				2560 2560 2560 2560 2560 2560 2560 2560 2560 2560 2560 2560 2560 2560 2560 2560 2560 2560
				2560 2560 2560 2560 2560 2560 2560 2560 2560 2560 2560 2560 2560 2560 2560 2560 2560 2560
				2560 2560 2560 2560 2560 2560 2560 2560 2560 2560 2560 2560 2560 2560 2560 2560 2560 2560
				2560 2560 2560 2560 2560 2560 2560 2560 2560 2560 2560 2560 2560 2560 2560 2560 2560 2560
				2560 2560 2560 2560 2560 2560 2560 2560 2560 2560 2560 2560 2560 2560 2560 2560 2560 2560
				2560 2560 2560 2560 2560 2560 2560 2560 2560 2560 2560 2560 2560 2560 2560 2560 2560 2560
				2560 2560 2560 2560 2560 2560 2560 2560 2560 2560 2560 2560 2560 2560 2560 2560 2560 2560
				2560 2560 2560 2560 2560 2560 2560 2560 2560 2560 2560 2560 2560 2560 2560 2560 2560 2560
				2560 2560 2560 2560 2560 2560 2560 2560 2560 2560 2560 2560 2560 2560 2560 2560 2560 2560
				2560 2560 2560 2560 2560 2560 2560 2560 2560 2560 2560 2560 2560 2560 2560 2560 2560 2560
				2560 2560 2560 2560 2560 2560 2560 2560 2560 2560 2560 2560 2560 2560 2560 2560 2560 2560
				2560 2560 2560 2560 2560 2560 2560 2560 2560 2560 2560 2560 2560 2560 2560 2560 2560 2560
				2560 2560 2560 2560 2560 2560 2560 2560 2560 2560 2560 2560 2560 2560 2560 2560 2560 2560
				2560 2560 2560 2560 2560 2560 2560 2560 2560 2560 2560 2560 2560 2560 2560 2560 2560 2560
				2560 2560 2560 2560 2560 2560 2560 2560 2560 2560 2560 2560 2560 2560 2560 2560 2560 2560
				2560 2560 2560 2560 2560 2560 2560 2560 2560 2560 2560 2560 2560 2560 2560 2560 2560 2560
				2560 2560 2560 2560 2560 2560 2560 2560 2560 2560 2560 2560 2560 2560 2560 2560 2560 2560
				2560 2560 2560 2560 2560 2560 2560 2560 2560 2560 2560 2560 2560 2560 2560 2560 2560 2560
				2560 2560 2560 2560 2560 2560 2560 2560 2560 2560 2560 2560 2560 2560 2560 2560 2560 2560
				2560 2560 2560 2560 2560 2560 2560 2560 2560 2560 2560 2560 2560 2560 2560 2560 2560 2560
				2560 2560 2560 2560 2560 2560 2560 2560 2560 2560 2560 2560 2560 2560 2560 2560 2560 2560
				2560 2560 2560>;

			PS_Config_Lmt_FW_Rawdata_N = <
				240 240 240 240 240 240 240 240 240 240 240 240 240 240 240 240 240 240
				240 240 240 240 240 240 240 240 240 240 240 240 240 240 240 240 240 240
				240 240 240 240 240 240 240 240 240 240 240 240 240 240 240 240 240 240
				240 240 240 240 240 240 240 240 240 240 240 240 240 240 240 240 240 240
				240 240 240 240 240 240 240 240 240 240 240 240 240 240 240 240 240 240
				240 240 240 240 240 240 240 240 240 240 240 240 240 240 240 240 240 240
				240 240 240 240 240 240 240 240 240 240 240 240 240 240 240 240 240 240
				240 240 240 240 240 240 240 240 240 240 240 240 240 240 240 240 240 240
				240 240 240 240 240 240 240 240 240 240 240 240 240 240 240 240 240 240
				240 240 240 240 240 240 240 240 240 240 240 240 240 240 240 240 240 240
				240 240 240 240 240 240 240 240 240 240 240 240 240 240 240 240 240 240
				240 240 240 240 240 240 240 240 240 240 240 240 240 240 240 240 240 240
				240 240 240 240 240 240 240 240 240 240 240 240 240 240 240 240 240 240
				240 240 240 240 240 240 240 240 240 240 240 240 240 240 240 240 240 240
				240 240 240 240 240 240 240 240 240 240 240 240 240 240 240 240 240 240
				240 240 240 240 240 240 240 240 240 240 240 240 240 240 240 240 240 240
				240 240 240 240 240 240 240 240 240 240 240 240 240 240 240 240 240 240
				240 240 240 240 240 240 240 240 240 240 240 240 240 240 240 240 240 240
				240 240 240 240 240 240 240 240 240 240 240 240 240 240 240 240 240 240
				240 240 240 240 240 240 240 240 240 240 240 240 240 240 240 240 240 240
				240 240 240 240 240 240 240 240 240 240 240 240 240 240 240 240 240 240
				240 240 240 240 240 240 240 240 240 240 240 240 240 240 240 240 240 240
				240 240 240 240 240 240 240 240 240 240 240 240 240 240 240 240 240 240
				240 240 240 240 240 240 240 240 240 240 240 240 240 240 240 240 240 240
				240 240 240 240 240 240 240 240 240 240 240 240 240 240 240 240 240 240
				240 240 240 240 240 240 240 240 240 240 240 240 240 240 240 240 240 240
				240 240 240 240 240 240 240 240 240 240 240 240 240 240 240 240 240 240
				240 240 240 240 240 240 240 240 240 240 240 240 240 240 240 240 240 240
				240 240 240 240 240 240 240 240 240 240 240 240 240 240 240 240 240 240
				240 240 240 240 240 240 240 240 240 240 240 240 240 240 240 240 240 240
				240 240 240 240 240 240 240 240 240 240 240 240 240 240 240 240 240 240
				240 240 240 240 240 240 240 240 240 240 240 240 240 240 240 240 240 240
				240 240 240 240 240 240 240 240 240 240 240 240 240 240 240 240 240 240
				240 240 240 240 240 240 240 240 240 240 240 240 240 240 240 240 240 240
				240 240 240 240 240 240 240 240 240 240 240 240 240 240 240 240 240 240
				240 240 240 240 240 240 240 240 240 240 240 240 240 240 240 240 240 240
				240 240 240>;

			PS_Config_Lmt_FW_CC_P = <
				314 314 314 314 314 314 314 314 314 314 314 314 314 314 314 314 314 314
				314 314 314 314 314 314 314 314 314 314 314 314 314 314 314 314 314 314
				314 314 314 314 314 314 314 314 314 314 314 314 314 314 314 314 314 314
				314 314 314 314 314 314 314 314 314 314 314 314 314 314 314 314 314 314
				314 314 314 314 314 314 314 314 314 314 314 314 314 314 314 314 314 314
				314 314 314 314 314 314 314 314 314 314 314 314 314 314 314 314 314 314
				314 314 314 314 314 314 314 314 314 314 314 314 314 314 314 314 314 314
				314 314 314 314 314 314 314 314 314 314 314 314 314 314 314 314 314 314
				314 314 314 314 314 314 314 314 314 314 314 314 314 314 314 314 314 314
				314 314 314 314 314 314 314 314 314 314 314 314 314 314 314 314 314 314
				314 314 314 314 314 314 314 314 314 314 314 314 314 314 314 314 314 314
				314 314 314 314 314 314 314 314 314 314 314 314 314 314 314 314 314 314
				314 314 314 314 314 314 314 314 314 314 314 314 314 314 314 314 314 314
				314 314 314 314 314 314 314 314 314 314 314 314 314 314 314 314 314 314
				314 314 314 314 314 314 314 314 314 314 314 314 314 314 314 314 314 314
				314 314 314 314 314 314 314 314 314 314 314 314 314 314 314 314 314 314
				314 314 314 314 314 314 314 314 314 314 314 314 314 314 314 314 314 314
				314 314 314 314 314 314 314 314 314 314 314 314 314 314 314 314 314 314
				314 314 314 314 314 314 314 314 314 314 314 314 314 314 314 314 314 314
				314 314 314 314 314 314 314 314 314 314 314 314 314 314 314 314 314 314
				314 314 314 314 314 314 314 314 314 314 314 314 314 314 314 314 314 314
				314 314 314 314 314 314 314 314 314 314 314 314 314 314 314 314 314 314
				314 314 314 314 314 314 314 314 314 314 314 314 314 314 314 314 314 314
				314 314 314 314 314 314 314 314 314 314 314 314 314 314 314 314 314 314
				314 314 314 314 314 314 314 314 314 314 314 314 314 314 314 314 314 314
				314 314 314 314 314 314 314 314 314 314 314 314 314 314 314 314 314 314
				314 314 314 314 314 314 314 314 314 314 314 314 314 314 314 314 314 314
				314 314 314 314 314 314 314 314 314 314 314 314 314 314 314 314 314 314
				314 314 314 314 314 314 314 314 314 314 314 314 314 314 314 314 314 314
				314 314 314 314 314 314 314 314 314 314 314 314 314 314 314 314 314 314
				314 314 314 314 314 314 314 314 314 314 314 314 314 314 314 314 314 314
				314 314 314 314 314 314 314 314 314 314 314 314 314 314 314 314 314 314
				314 314 314 314 314 314 314 314 314 314 314 314 314 314 314 314 314 314
				314 314 314 314 314 314 314 314 314 314 314 314 314 314 314 314 314 314
				314 314 314 314 314 314 314 314 314 314 314 314 314 314 314 314 314 314
				314 314 314 314 314 314 314 314 314 314 314 314 314 314 314 314 314 314
				314 314 314>;

			PS_Config_Lmt_FW_CC_N = <
				0 0 0 0 0 0 0 0 0 0 0 0 0 0 0 0 0 0
				0 0 0 0 0 0 0 0 0 0 0 0 0 0 0 0 0 0
				0 0 0 0 0 0 0 0 0 0 0 0 0 0 0 0 0 0
				0 0 0 0 0 0 0 0 0 0 0 0 0 0 0 0 0 0
				0 0 0 0 0 0 0 0 0 0 0 0 0 0 0 0 0 0
				0 0 0 0 0 0 0 0 0 0 0 0 0 0 0 0 0 0
				0 0 0 0 0 0 0 0 0 0 0 0 0 0 0 0 0 0
				0 0 0 0 0 0 0 0 0 0 0 0 0 0 0 0 0 0
				0 0 0 0 0 0 0 0 0 0 0 0 0 0 0 0 0 0
				0 0 0 0 0 0 0 0 0 0 0 0 0 0 0 0 0 0
				0 0 0 0 0 0 0 0 0 0 0 0 0 0 0 0 0 0
				0 0 0 0 0 0 0 0 0 0 0 0 0 0 0 0 0 0
				0 0 0 0 0 0 0 0 0 0 0 0 0 0 0 0 0 0
				0 0 0 0 0 0 0 0 0 0 0 0 0 0 0 0 0 0
				0 0 0 0 0 0 0 0 0 0 0 0 0 0 0 0 0 0
				0 0 0 0 0 0 0 0 0 0 0 0 0 0 0 0 0 0
				0 0 0 0 0 0 0 0 0 0 0 0 0 0 0 0 0 0
				0 0 0 0 0 0 0 0 0 0 0 0 0 0 0 0 0 0
				0 0 0 0 0 0 0 0 0 0 0 0 0 0 0 0 0 0
				0 0 0 0 0 0 0 0 0 0 0 0 0 0 0 0 0 0
				0 0 0 0 0 0 0 0 0 0 0 0 0 0 0 0 0 0
				0 0 0 0 0 0 0 0 0 0 0 0 0 0 0 0 0 0
				0 0 0 0 0 0 0 0 0 0 0 0 0 0 0 0 0 0
				0 0 0 0 0 0 0 0 0 0 0 0 0 0 0 0 0 0
				0 0 0 0 0 0 0 0 0 0 0 0 0 0 0 0 0 0
				0 0 0 0 0 0 0 0 0 0 0 0 0 0 0 0 0 0
				0 0 0 0 0 0 0 0 0 0 0 0 0 0 0 0 0 0
				0 0 0 0 0 0 0 0 0 0 0 0 0 0 0 0 0 0
				0 0 0 0 0 0 0 0 0 0 0 0 0 0 0 0 0 0
				0 0 0 0 0 0 0 0 0 0 0 0 0 0 0 0 0 0
				0 0 0 0 0 0 0 0 0 0 0 0 0 0 0 0 0 0
				0 0 0 0 0 0 0 0 0 0 0 0 0 0 0 0 0 0
				0 0 0 0 0 0 0 0 0 0 0 0 0 0 0 0 0 0
				0 0 0 0 0 0 0 0 0 0 0 0 0 0 0 0 0 0
				0 0 0 0 0 0 0 0 0 0 0 0 0 0 0 0 0 0
				0 0 0 0 0 0 0 0 0 0 0 0 0 0 0 0 0 0
				0 0 0>;

			PS_Config_Lmt_FW_Diff_P = <
				75 75 75 75 75 75 75 75 75 75 75 75 75 75 75 75 75 75
				75 75 75 75 75 75 75 75 75 75 75 75 75 75 75 75 75 75
				75 75 75 75 75 75 75 75 75 75 75 75 75 75 75 75 75 75
				75 75 75 75 75 75 75 75 75 75 75 75 75 75 75 75 75 75
				75 75 75 75 75 75 75 75 75 75 75 75 75 75 75 75 75 75
				75 75 75 75 75 75 75 75 75 75 75 75 75 75 75 75 75 75
				75 75 75 75 75 75 75 75 75 75 75 75 75 75 75 75 75 75
				75 75 75 75 75 75 75 75 75 75 75 75 75 75 75 75 75 75
				75 75 75 75 75 75 75 75 75 75 75 75 75 75 75 75 75 75
				75 75 75 75 75 75 75 75 75 75 75 75 75 75 75 75 75 75
				75 75 75 75 75 75 75 75 75 75 75 75 75 75 75 75 75 75
				75 75 75 75 75 75 75 75 75 75 75 75 75 75 75 75 75 75
				75 75 75 75 75 75 75 75 75 75 75 75 75 75 75 75 75 75
				75 75 75 75 75 75 75 75 75 75 75 75 75 75 75 75 75 75
				75 75 75 75 75 75 75 75 75 75 75 75 75 75 75 75 75 75
				75 75 75 75 75 75 75 75 75 75 75 75 75 75 75 75 75 75
				75 75 75 75 75 75 75 75 75 75 75 75 75 75 75 75 75 75
				75 75 75 75 75 75 75 75 75 75 75 75 75 75 75 75 75 75
				75 75 75 75 75 75 75 75 75 75 75 75 75 75 75 75 75 75
				75 75 75 75 75 75 75 75 75 75 75 75 75 75 75 75 75 75
				75 75 75 75 75 75 75 75 75 75 75 75 75 75 75 75 75 75
				75 75 75 75 75 75 75 75 75 75 75 75 75 75 75 75 75 75
				75 75 75 75 75 75 75 75 75 75 75 75 75 75 75 75 75 75
				75 75 75 75 75 75 75 75 75 75 75 75 75 75 75 75 75 75
				75 75 75 75 75 75 75 75 75 75 75 75 75 75 75 75 75 75
				75 75 75 75 75 75 75 75 75 75 75 75 75 75 75 75 75 75
				75 75 75 75 75 75 75 75 75 75 75 75 75 75 75 75 75 75
				75 75 75 75 75 75 75 75 75 75 75 75 75 75 75 75 75 75
				75 75 75 75 75 75 75 75 75 75 75 75 75 75 75 75 75 75
				75 75 75 75 75 75 75 75 75 75 75 75 75 75 75 75 75 75
				75 75 75 75 75 75 75 75 75 75 75 75 75 75 75 75 75 75
				75 75 75 75 75 75 75 75 75 75 75 75 75 75 75 75 75 75
				75 75 75 75 75 75 75 75 75 75 75 75 75 75 75 75 75 75
				75 75 75 75 75 75 75 75 75 75 75 75 75 75 75 75 75 75
				75 75 75 75 75 75 75 75 75 75 75 75 75 75 75 75 75 75
				75 75 75 75 75 75 75 75 75 75 75 75 75 75 75 75 75 75
				75 75 75>;

			PS_Config_Lmt_FW_Diff_N = <
				(-75) (-75) (-75) (-75) (-75) (-75) (-75) (-75) (-75) (-75) (-75) (-75) (-75) (-75) (-75) (-75) (-75) (-75)
				(-75) (-75) (-75) (-75) (-75) (-75) (-75) (-75) (-75) (-75) (-75) (-75) (-75) (-75) (-75) (-75) (-75) (-75)
				(-75) (-75) (-75) (-75) (-75) (-75) (-75) (-75) (-75) (-75) (-75) (-75) (-75) (-75) (-75) (-75) (-75) (-75)
				(-75) (-75) (-75) (-75) (-75) (-75) (-75) (-75) (-75) (-75) (-75) (-75) (-75) (-75) (-75) (-75) (-75) (-75)
				(-75) (-75) (-75) (-75) (-75) (-75) (-75) (-75) (-75) (-75) (-75) (-75) (-75) (-75) (-75) (-75) (-75) (-75)
				(-75) (-75) (-75) (-75) (-75) (-75) (-75) (-75) (-75) (-75) (-75) (-75) (-75) (-75) (-75) (-75) (-75) (-75)
				(-75) (-75) (-75) (-75) (-75) (-75) (-75) (-75) (-75) (-75) (-75) (-75) (-75) (-75) (-75) (-75) (-75) (-75)
				(-75) (-75) (-75) (-75) (-75) (-75) (-75) (-75) (-75) (-75) (-75) (-75) (-75) (-75) (-75) (-75) (-75) (-75)
				(-75) (-75) (-75) (-75) (-75) (-75) (-75) (-75) (-75) (-75) (-75) (-75) (-75) (-75) (-75) (-75) (-75) (-75)
				(-75) (-75) (-75) (-75) (-75) (-75) (-75) (-75) (-75) (-75) (-75) (-75) (-75) (-75) (-75) (-75) (-75) (-75)
				(-75) (-75) (-75) (-75) (-75) (-75) (-75) (-75) (-75) (-75) (-75) (-75) (-75) (-75) (-75) (-75) (-75) (-75)
				(-75) (-75) (-75) (-75) (-75) (-75) (-75) (-75) (-75) (-75) (-75) (-75) (-75) (-75) (-75) (-75) (-75) (-75)
				(-75) (-75) (-75) (-75) (-75) (-75) (-75) (-75) (-75) (-75) (-75) (-75) (-75) (-75) (-75) (-75) (-75) (-75)
				(-75) (-75) (-75) (-75) (-75) (-75) (-75) (-75) (-75) (-75) (-75) (-75) (-75) (-75) (-75) (-75) (-75) (-75)
				(-75) (-75) (-75) (-75) (-75) (-75) (-75) (-75) (-75) (-75) (-75) (-75) (-75) (-75) (-75) (-75) (-75) (-75)
				(-75) (-75) (-75) (-75) (-75) (-75) (-75) (-75) (-75) (-75) (-75) (-75) (-75) (-75) (-75) (-75) (-75) (-75)
				(-75) (-75) (-75) (-75) (-75) (-75) (-75) (-75) (-75) (-75) (-75) (-75) (-75) (-75) (-75) (-75) (-75) (-75)
				(-75) (-75) (-75) (-75) (-75) (-75) (-75) (-75) (-75) (-75) (-75) (-75) (-75) (-75) (-75) (-75) (-75) (-75)
				(-75) (-75) (-75) (-75) (-75) (-75) (-75) (-75) (-75) (-75) (-75) (-75) (-75) (-75) (-75) (-75) (-75) (-75)
				(-75) (-75) (-75) (-75) (-75) (-75) (-75) (-75) (-75) (-75) (-75) (-75) (-75) (-75) (-75) (-75) (-75) (-75)
				(-75) (-75) (-75) (-75) (-75) (-75) (-75) (-75) (-75) (-75) (-75) (-75) (-75) (-75) (-75) (-75) (-75) (-75)
				(-75) (-75) (-75) (-75) (-75) (-75) (-75) (-75) (-75) (-75) (-75) (-75) (-75) (-75) (-75) (-75) (-75) (-75)
				(-75) (-75) (-75) (-75) (-75) (-75) (-75) (-75) (-75) (-75) (-75) (-75) (-75) (-75) (-75) (-75) (-75) (-75)
				(-75) (-75) (-75) (-75) (-75) (-75) (-75) (-75) (-75) (-75) (-75) (-75) (-75) (-75) (-75) (-75) (-75) (-75)
				(-75) (-75) (-75) (-75) (-75) (-75) (-75) (-75) (-75) (-75) (-75) (-75) (-75) (-75) (-75) (-75) (-75) (-75)
				(-75) (-75) (-75) (-75) (-75) (-75) (-75) (-75) (-75) (-75) (-75) (-75) (-75) (-75) (-75) (-75) (-75) (-75)
				(-75) (-75) (-75) (-75) (-75) (-75) (-75) (-75) (-75) (-75) (-75) (-75) (-75) (-75) (-75) (-75) (-75) (-75)
				(-75) (-75) (-75) (-75) (-75) (-75) (-75) (-75) (-75) (-75) (-75) (-75) (-75) (-75) (-75) (-75) (-75) (-75)
				(-75) (-75) (-75) (-75) (-75) (-75) (-75) (-75) (-75) (-75) (-75) (-75) (-75) (-75) (-75) (-75) (-75) (-75)
				(-75) (-75) (-75) (-75) (-75) (-75) (-75) (-75) (-75) (-75) (-75) (-75) (-75) (-75) (-75) (-75) (-75) (-75)
				(-75) (-75) (-75) (-75) (-75) (-75) (-75) (-75) (-75) (-75) (-75) (-75) (-75) (-75) (-75) (-75) (-75) (-75)
				(-75) (-75) (-75) (-75) (-75) (-75) (-75) (-75) (-75) (-75) (-75) (-75) (-75) (-75) (-75) (-75) (-75) (-75)
				(-75) (-75) (-75) (-75) (-75) (-75) (-75) (-75) (-75) (-75) (-75) (-75) (-75) (-75) (-75) (-75) (-75) (-75)
				(-75) (-75) (-75) (-75) (-75) (-75) (-75) (-75) (-75) (-75) (-75) (-75) (-75) (-75) (-75) (-75) (-75) (-75)
				(-75) (-75) (-75) (-75) (-75) (-75) (-75) (-75) (-75) (-75) (-75) (-75) (-75) (-75) (-75) (-75) (-75) (-75)
				(-75) (-75) (-75) (-75) (-75) (-75) (-75) (-75) (-75) (-75) (-75) (-75) (-75) (-75) (-75) (-75) (-75) (-75)
				(-75) (-75) (-75)>;

			PS_Config_Diff_Test_Frame = <50>;
		};
/*for Xiaomi J19 672D BOE6.53" DJN module*/
		novatek-mp-criteria-5944@0 {
			#address-cells = <1>;
			#size-cells = <0>;
			compatible = "novatek-mp-criteria-5944";

			/* MP Config */
			IC_X_CFG_SIZE = <18>;
			IC_Y_CFG_SIZE = <36>;
			IC_KEY_CFG_SIZE = <4>;
			X_Channel = <18>;
			Y_Channel = <36>;
			AIN_X = <0 1 2 3 4 5 6 7 8 9 10 11 12 13 14 15 16 17>;
			AIN_Y = <0 1 2 3 4 5 6 7 8 9 10 11 12 13 14 15 16 17
						18 19 20 21 22 23 24 25 26 27 28 29 30 31 32 33 34 35>;
			AIN_KEY = <0 1 2 0xFF>;

			/* MP Criteria */
			PS_Config_Lmt_Short_Rawdata_P = <
				14008 14008 14008 14008 14008 14008 14008 14008 14008 14008 14008 14008 14008 14008 14008 14008 14008 14008
				14008 14008 14008 14008 14008 14008 14008 14008 14008 14008 14008 14008 14008 14008 14008 14008 14008 14008
				14008 14008 14008 14008 14008 14008 14008 14008 14008 14008 14008 14008 14008 14008 14008 14008 14008 14008
				14008 14008 14008 14008 14008 14008 14008 14008 14008 14008 14008 14008 14008 14008 14008 14008 14008 14008
				14008 14008 14008 14008 14008 14008 14008 14008 14008 14008 14008 14008 14008 14008 14008 14008 14008 14008
				14008 14008 14008 14008 14008 14008 14008 14008 14008 14008 14008 14008 14008 14008 14008 14008 14008 14008
				14008 14008 14008 14008 14008 14008 14008 14008 14008 14008 14008 14008 14008 14008 14008 14008 14008 14008
				14008 14008 14008 14008 14008 14008 14008 14008 14008 14008 14008 14008 14008 14008 14008 14008 14008 14008
				14008 14008 14008 14008 14008 14008 14008 14008 14008 14008 14008 14008 14008 14008 14008 14008 14008 14008
				14008 14008 14008 14008 14008 14008 14008 14008 14008 14008 14008 14008 14008 14008 14008 14008 14008 14008
				14008 14008 14008 14008 14008 14008 14008 14008 14008 14008 14008 14008 14008 14008 14008 14008 14008 14008
				14008 14008 14008 14008 14008 14008 14008 14008 14008 14008 14008 14008 14008 14008 14008 14008 14008 14008
				14008 14008 14008 14008 14008 14008 14008 14008 14008 14008 14008 14008 14008 14008 14008 14008 14008 14008
				14008 14008 14008 14008 14008 14008 14008 14008 14008 14008 14008 14008 14008 14008 14008 14008 14008 14008
				14008 14008 14008 14008 14008 14008 14008 14008 14008 14008 14008 14008 14008 14008 14008 14008 14008 14008
				14008 14008 14008 14008 14008 14008 14008 14008 14008 14008 14008 14008 14008 14008 14008 14008 14008 14008
				14008 14008 14008 14008 14008 14008 14008 14008 14008 14008 14008 14008 14008 14008 14008 14008 14008 14008
				14008 14008 14008 14008 14008 14008 14008 14008 14008 14008 14008 14008 14008 14008 14008 14008 14008 14008
				14008 14008 14008 14008 14008 14008 14008 14008 14008 14008 14008 14008 14008 14008 14008 14008 14008 14008
				14008 14008 14008 14008 14008 14008 14008 14008 14008 14008 14008 14008 14008 14008 14008 14008 14008 14008
				14008 14008 14008 14008 14008 14008 14008 14008 14008 14008 14008 14008 14008 14008 14008 14008 14008 14008
				14008 14008 14008 14008 14008 14008 14008 14008 14008 14008 14008 14008 14008 14008 14008 14008 14008 14008
				14008 14008 14008 14008 14008 14008 14008 14008 14008 14008 14008 14008 14008 14008 14008 14008 14008 14008
				14008 14008 14008 14008 14008 14008 14008 14008 14008 14008 14008 14008 14008 14008 14008 14008 14008 14008
				14008 14008 14008 14008 14008 14008 14008 14008 14008 14008 14008 14008 14008 14008 14008 14008 14008 14008
				14008 14008 14008 14008 14008 14008 14008 14008 14008 14008 14008 14008 14008 14008 14008 14008 14008 14008
				14008 14008 14008 14008 14008 14008 14008 14008 14008 14008 14008 14008 14008 14008 14008 14008 14008 14008
				14008 14008 14008 14008 14008 14008 14008 14008 14008 14008 14008 14008 14008 14008 14008 14008 14008 14008
				14008 14008 14008 14008 14008 14008 14008 14008 14008 14008 14008 14008 14008 14008 14008 14008 14008 14008
				14008 14008 14008 14008 14008 14008 14008 14008 14008 14008 14008 14008 14008 14008 14008 14008 14008 14008
				14008 14008 14008 14008 14008 14008 14008 14008 14008 14008 14008 14008 14008 14008 14008 14008 14008 14008
				14008 14008 14008 14008 14008 14008 14008 14008 14008 14008 14008 14008 14008 14008 14008 14008 14008 14008
				14008 14008 14008 14008 14008 14008 14008 14008 14008 14008 14008 14008 14008 14008 14008 14008 14008 14008
				14008 14008 14008 14008 14008 14008 14008 14008 14008 14008 14008 14008 14008 14008 14008 14008 14008 14008
				14008 14008 14008 14008 14008 14008 14008 14008 14008 14008 14008 14008 14008 14008 14008 14008 14008 14008
				14008 14008 14008 14008 14008 14008 14008 14008 14008 14008 14008 14008 14008 14008 14008 14008 14008 14008
				14008 14008 14008>;

			PS_Config_Lmt_Short_Rawdata_N = <
				10100 10100 10100 10100 10100 10100 10100 10100 10100 10100 10100 10100 10100 10100 10100 10100 10100 10100
				10100 10100 10100 10100 10100 10100 10100 10100 10100 10100 10100 10100 10100 10100 10100 10100 10100 10100
				10100 10100 10100 10100 10100 10100 10100 10100 10100 10100 10100 10100 10100 10100 10100 10100 10100 10100
				10100 10100 10100 10100 10100 10100 10100 10100 10100 10100 10100 10100 10100 10100 10100 10100 10100 10100
				10100 10100 10100 10100 10100 10100 10100 10100 10100 10100 10100 10100 10100 10100 10100 10100 10100 10100
				10100 10100 10100 10100 10100 10100 10100 10100 10100 10100 10100 10100 10100 10100 10100 10100 10100 10100
				10100 10100 10100 10100 10100 10100 10100 10100 10100 10100 10100 10100 10100 10100 10100 10100 10100 10100
				10100 10100 10100 10100 10100 10100 10100 10100 10100 10100 10100 10100 10100 10100 10100 10100 10100 10100
				10100 10100 10100 10100 10100 10100 10100 10100 10100 10100 10100 10100 10100 10100 10100 10100 10100 10100
				10100 10100 10100 10100 10100 10100 10100 10100 10100 10100 10100 10100 10100 10100 10100 10100 10100 10100
				10100 10100 10100 10100 10100 10100 10100 10100 10100 10100 10100 10100 10100 10100 10100 10100 10100 10100
				10100 10100 10100 10100 10100 10100 10100 10100 10100 10100 10100 10100 10100 10100 10100 10100 10100 10100
				10100 10100 10100 10100 10100 10100 10100 10100 10100 10100 10100 10100 10100 10100 10100 10100 10100 10100
				10100 10100 10100 10100 10100 10100 10100 10100 10100 10100 10100 10100 10100 10100 10100 10100 10100 10100
				10100 10100 10100 10100 10100 10100 10100 10100 10100 10100 10100 10100 10100 10100 10100 10100 10100 10100
				10100 10100 10100 10100 10100 10100 10100 10100 10100 10100 10100 10100 10100 10100 10100 10100 10100 10100
				10100 10100 10100 10100 10100 10100 10100 10100 10100 10100 10100 10100 10100 10100 10100 10100 10100 10100
				10100 10100 10100 10100 10100 10100 10100 10100 10100 10100 10100 10100 10100 10100 10100 10100 10100 10100
				10100 10100 10100 10100 10100 10100 10100 10100 10100 10100 10100 10100 10100 10100 10100 10100 10100 10100
				10100 10100 10100 10100 10100 10100 10100 10100 10100 10100 10100 10100 10100 10100 10100 10100 10100 10100
				10100 10100 10100 10100 10100 10100 10100 10100 10100 10100 10100 10100 10100 10100 10100 10100 10100 10100
				10100 10100 10100 10100 10100 10100 10100 10100 10100 10100 10100 10100 10100 10100 10100 10100 10100 10100
				10100 10100 10100 10100 10100 10100 10100 10100 10100 10100 10100 10100 10100 10100 10100 10100 10100 10100
				10100 10100 10100 10100 10100 10100 10100 10100 10100 10100 10100 10100 10100 10100 10100 10100 10100 10100
				10100 10100 10100 10100 10100 10100 10100 10100 10100 10100 10100 10100 10100 10100 10100 10100 10100 10100
				10100 10100 10100 10100 10100 10100 10100 10100 10100 10100 10100 10100 10100 10100 10100 10100 10100 10100
				10100 10100 10100 10100 10100 10100 10100 10100 10100 10100 10100 10100 10100 10100 10100 10100 10100 10100
				10100 10100 10100 10100 10100 10100 10100 10100 10100 10100 10100 10100 10100 10100 10100 10100 10100 10100
				10100 10100 10100 10100 10100 10100 10100 10100 10100 10100 10100 10100 10100 10100 10100 10100 10100 10100
				10100 10100 10100 10100 10100 10100 10100 10100 10100 10100 10100 10100 10100 10100 10100 10100 10100 10100
				10100 10100 10100 10100 10100 10100 10100 10100 10100 10100 10100 10100 10100 10100 10100 10100 10100 10100
				10100 10100 10100 10100 10100 10100 10100 10100 10100 10100 10100 10100 10100 10100 10100 10100 10100 10100
				10100 10100 10100 10100 10100 10100 10100 10100 10100 10100 10100 10100 10100 10100 10100 10100 10100 10100
				10100 10100 10100 10100 10100 10100 10100 10100 10100 10100 10100 10100 10100 10100 10100 10100 10100 10100
				10100 10100 10100 10100 10100 10100 10100 10100 10100 10100 10100 10100 10100 10100 10100 10100 10100 10100
				10100 10100 10100 10100 10100 10100 10100 10100 10100 10100 10100 10100 10100 10100 10100 10100 10100 10100
				10000 10000 10000>;

			PS_Config_Lmt_Open_Rawdata_P = <
				3279	3431	3560	3650	3693	3720	3756	3672	65535	65535	3620	3696	3665	3633	3599	3546	3445	3289
				3220	3506	3613	3720	3769	3801	3854	3482	3938	3800	3374	3711	3682	3651	3625	3580	3525	3247
				3259	3520	3598	3688	3731	3756	3795	3826	3893	3762	3731	3700	3667	3633	3598	3550	3490	3240
				3420	3520	3618	3730	3787	3825	3865	3913	3952	3767	3738	3713	3686	3653	3622	3583	3524	3485
				3448	3496	3590	3674	3725	3762	3795	3830	3892	3794	3763	3730	3683	3653	3613	3557	3508	3465
				3518	3576	3682	3780	3846	3888	3926	3965	4003	3871	3791	3765	3728	3711	3685	3646	3612	3570
				3511	3548	3637	3718	3780	3804	3840	3870	3944	3829	3788	3758	3728	3700	3667	3616	3576	3528
				3536	3543	3681	3783	3857	3892	3938	3973	4017	3885	3758	3759	3735	3709	3689	3648	3623	3585
				3517	3563	3636	3730	3793	3822	3853	3893	3961	3821	3779	3742	3704	3675	3643	3598	3552	3517
				3543	3606	3690	3801	3878	3921	3963	4008	4036	3871	3791	3760	3730	3704	3675	3639	3597	3571
				3531	3573	3611	3730	3809	3844	3874	3906	3970	3835	3797	3717	3716	3685	3651	3598	3555	3525
				3588	3647	3727	3819	3909	3948	3983	4017	4047	3919	3839	3801	3767	3752	3725	3688	3654	3633
				3602	3644	3709	3783	3861	3892	3926	3948	4008	3844	3811	3767	3734	3697	3667	3630	3588	3567
				3609	3671	3749	3829	3927	3965	4012	4046	4073	3902	3840	3797	3758	3730	3707	3682	3657	3636
				3623	3675	3730	3762	3879	3912	3945	3972	4017	3833	3805	3769	3681	3679	3653	3619	3580	3562
				3588	3658	3728	3814	3906	3949	3998	4032	4049	3860	3811	3784	3723	3689	3665	3637	3606	3595
				3560	3529	3563	3601	3623	3665	3710	3744	3780	3979	3930	3892	3829	3793	3703	3619	3536	3471
				3618	3598	3640	3693	3710	3774	3825	3864	3903	3983	3940	3912	3857	3816	3753	3682	3609	3611
				3605	3577	3611	3637	3633	3679	3724	3753	3783	3921	3884	3847	3800	3752	3692	3611	3548	3542
				3611	3591	3643	3685	3713	3745	3797	3825	3864	3969	3931	3902	3853	3823	3752	3678	3612	3611
				3602	3578	3608	3640	3660	3674	3720	3745	3779	3907	3865	3840	3795	3760	3682	3616	3542	3538
				3571	3559	3608	3662	3695	3685	3773	3807	3846	3906	3874	3844	3801	3763	3662	3630	3556	3560
				3531	3518	3559	3590	3613	3633	3675	3707	3738	3870	3828	3800	3742	3710	3634	3557	3482	3480
				3576	3577	3623	3669	3700	3725	3766	3802	3843	3900	3857	3832	3779	3753	3685	3616	3546	3556
				3552	3545	3584	3609	3632	3640	3678	3700	3734	3861	3819	3787	3738	3706	3647	3562	3499	3492
				3549	3553	3606	3646	3679	3693	3710	3766	3812	3867	3826	3795	3752	3720	3671	3563	3531	3527
				3499	3506	3541	3577	3594	3604	3634	3654	3692	3795	3758	3732	3686	3653	3599	3520	3448	3441
				3499	3510	3563	3616	3646	3661	3706	3731	3772	3816	3776	3751	3707	3672	3629	3556	3478	3478
				3447	3455	3499	3528	3546	3564	3595	3587	3650	3749	3711	3688	3630	3599	3553	3466	3370	3385
				3471	3492	3555	3595	3625	3648	3681	3696	3739	3791	3745	3727	3679	3655	3619	3541	3464	3465
				3420	3426	3480	3503	3524	3536	3569	3576	3618	3716	3682	3654	3609	3577	3542	3461	3385	3366
				3440	3461	3531	3569	3595	3612	3651	3664	3697	3716	3671	3646	3605	3581	3557	3482	3415	3395
				3367	3387	3441	3472	3492	3507	3539	3552	3571	3641	3612	3590	3543	3515	3482	3413	3332	3282
				3032	3378	3450	3501	3532	3553	3595	3620	3644	3647	3598	3578	3532	3500	3471	3410	3332	2996
				3011	3303	3368	3427	3448	3472	3499	3513	3549	3569	3538	3511	3461	3427	3392	3342	3272	2971
				3108	3286	3413	3483	3514	3548	3581	3609	3639	3620	3562	3535	3487	3465	3433	3394	3283	3111
				5120 5120 5120>;

			PS_Config_Lmt_Open_Rawdata_N = <
				1309	1355	1403	1440	1459	1469	1486	1465	(-65535)	(-65535)	1451	1470	1451	1432	1412	1385	1346	1297
				1288	1378	1421	1464	1484	1497	1519	1392	1565	1519	1355	1469	1456	1444	1432	1412	1388	1301
				1319	1403	1437	1474	1490	1497	1512	1525	1556	1502	1487	1471	1452	1436	1420	1399	1372	1294
				1359	1394	1433	1481	1505	1521	1540	1562	1581	1496	1475	1459	1443	1428	1415	1399	1373	1361
				1366	1384	1421	1456	1477	1490	1505	1519	1549	1511	1497	1481	1462	1450	1435	1411	1388	1374
				1394	1416	1460	1500	1528	1545	1563	1583	1602	1541	1506	1492	1475	1466	1453	1433	1419	1405
				1388	1401	1439	1473	1500	1508	1525	1540	1576	1525	1508	1495	1484	1471	1454	1430	1411	1396
				1399	1405	1459	1501	1535	1551	1572	1588	1608	1552	1502	1500	1490	1477	1466	1447	1436	1423
				1413	1429	1459	1498	1524	1537	1549	1567	1597	1528	1511	1495	1479	1468	1454	1436	1417	1406
				1418	1440	1475	1522	1554	1571	1588	1609	1622	1553	1519	1505	1491	1481	1469	1456	1436	1430
				1409	1423	1444	1493	1528	1541	1556	1571	1603	1543	1529	1498	1494	1482	1465	1439	1418	1411
				1428	1448	1485	1526	1568	1588	1603	1619	1635	1565	1530	1513	1498	1491	1481	1465	1452	1450
				1429	1443	1472	1504	1538	1549	1564	1573	1603	1542	1529	1511	1496	1481	1466	1448	1430	1424
				1439	1462	1497	1534	1578	1594	1614	1628	1641	1565	1539	1521	1502	1487	1475	1461	1446	1443
				1455	1473	1496	1514	1562	1575	1590	1601	1622	1553	1541	1525	1492	1490	1478	1461	1446	1448
				1445	1471	1501	1539	1580	1600	1625	1642	1651	1564	1543	1529	1502	1486	1472	1457	1447	1451
				1443	1418	1433	1448	1459	1475	1496	1513	1532	1624	1603	1585	1558	1541	1498	1459	1422	1411
				1460	1439	1457	1481	1492	1516	1537	1556	1576	1634	1614	1602	1577	1559	1527	1493	1460	1471
				1467	1444	1460	1473	1475	1492	1510	1522	1538	1610	1592	1576	1553	1532	1501	1464	1436	1445
				1466	1448	1470	1487	1499	1513	1538	1550	1567	1624	1608	1593	1571	1559	1526	1493	1465	1475
				1469	1446	1459	1474	1484	1492	1513	1524	1538	1604	1585	1572	1553	1538	1501	1470	1435	1444
				1456	1440	1461	1483	1496	1495	1531	1545	1564	1606	1591	1579	1560	1546	1503	1484	1449	1461
				1461	1445	1463	1476	1486	1492	1509	1522	1536	1592	1574	1561	1538	1526	1492	1456	1421	1432
				1469	1457	1477	1498	1513	1525	1546	1563	1583	1609	1593	1586	1561	1550	1519	1487	1456	1471
				1467	1452	1471	1484	1493	1498	1514	1523	1539	1598	1580	1563	1538	1524	1496	1456	1425	1435
				1464	1452	1475	1491	1507	1514	1526	1549	1571	1595	1576	1563	1542	1527	1505	1462	1444	1455
				1462	1451	1465	1479	1484	1487	1499	1508	1526	1579	1561	1550	1530	1516	1493	1457	1426	1435
				1450	1442	1462	1487	1502	1513	1535	1546	1566	1592	1574	1562	1542	1526	1508	1473	1436	1449
				1441	1430	1450	1465	1475	1484	1500	1499	1528	1561	1544	1534	1510	1497	1477	1438	1396	1414
				1454	1451	1477	1495	1508	1519	1534	1541	1561	1581	1562	1554	1535	1525	1508	1469	1433	1445
				1455	1444	1469	1478	1488	1492	1505	1509	1529	1549	1534	1525	1507	1495	1483	1447	1414	1418
				1442	1438	1469	1486	1499	1506	1524	1531	1544	1560	1538	1527	1510	1501	1493	1459	1429	1435
				1431	1426	1451	1463	1472	1476	1490	1497	1509	1522	1508	1499	1480	1468	1453	1426	1390	1384
				1288	1414	1447	1471	1484	1495	1514	1526	1538	1532	1510	1501	1483	1472	1461	1435	1402	1278
				1286	1392	1421	1446	1456	1466	1478	1484	1500	1508	1495	1483	1462	1450	1435	1412	1379	1268
				1337	1406	1463	1496	1511	1525	1541	1553	1568	1542	1517	1507	1488	1480	1465	1447	1396	1328
				(-511) (-511) (-511)>;

			PS_Config_Lmt_FW_Rawdata_P = <
				1064	1141	1132	1090	1143	1100	1106	1128	65535	65535	1085	1090	1096	1111	1071	1093	1078	1078
				1093	1118	1107	1132	1114	1124	1103	1110	1100	1118	1096	1092	1104	1092	1100	1100	1100	1129
				1107	1134	1134	1128	1128	1120	1134	1124	1100	1120	1096	1125	1115	1110	1108	1096	1097	1117
				1100	1097	1080	1093	1104	1108	1111	1134	1110	1118	1125	1120	1122	1107	1113	1121	1132	1092
				1089	1134	1152	1157	1143	1142	1149	1138	1086	1113	1138	1099	1106	1132	1104	1115	1099	1139
				1114	1127	1139	1134	1124	1134	1142	1099	1141	1113	1127	1106	1127	1096	1125	1108	1097	1106
				1110	1115	1115	1107	1103	1096	1103	1100	1117	1121	1106	1111	1092	1134	1114	1110	1114	1114
				1087	1093	1089	1096	1104	1103	1097	1108	1100	1120	1124	1129	1121	1104	1122	1122	1120	1108
				1089	1117	1135	1110	1129	1118	1143	1085	1124	1120	1131	1120	1108	1097	1114	1110	1127	1128
				1134	1082	1083	1087	1075	1110	1092	1136	1096	1092	1100	1065	1082	1069	1079	1090	1085	1118
				1138	1087	1092	1086	1083	1104	1093	1135	1101	1120	1125	1122	1117	1113	1128	1131	1138	1120
				1092	1134	1135	1146	1135	1157	1141	1093	1149	1110	1087	1087	1085	1099	1090	1099	1103	1139
				1103	1143	1141	1115	1149	1101	1099	1103	1131	1101	1131	1071	1068	1062	1066	1059	1051	1141
				1118	1125	1141	1118	1132	1128	1136	1104	1136	1114	1121	1106	1101	1094	1104	1087	1083	1160
				1090	1152	1153	1131	1132	1066	1066	1073	1129	1101	1122	1111	1117	1125	1124	1107	1090	1107
				1148	1101	1090	1120	1107	1080	1097	1120	1148	1114	1113	1118	1115	1094	1099	1113	1118	1100
				1099	1101	1092	1082	1094	1110	1113	1103	1099	1107	1103	1092	1106	1099	1107	1089	1104	1107
				1113	1107	1113	1118	1106	1113	1115	1110	1093	1115	1107	1104	1104	1108	1114	1111	1087	1132
				1089	1146	1135	1135	1125	1122	1145	1127	1143	1145	1111	1122	1103	1086	1107	1092	1111	1108
				1092	1122	1121	1124	1104	1108	1118	1115	1150	1117	1125	1120	1101	1118	1128	1118	1120	1111
				1087	1143	1124	1135	1128	1134	1125	1127	1097	1073	1122	1092	1159	1178	1157	1169	1155	1125
				1092	1083	1090	1092	1086	1099	1101	1100	1111	1129	1128	1121	1111	1115	1118	1113	1128	1085
				1125	1115	1125	1135	1124	1139	1129	1142	1145	1108	1111	1115	1125	1131	1120	1121	1128	1111
				1145	1117	1142	1135	1143	1141	1108	1099	1101	1127	1104	1100	1122	1103	1100	1100	1083	1142
				1129	1104	1101	1110	1131	1128	1113	1117	1142	1113	1128	1132	1110	1107	1106	1097	1101	1103
				1113	1149	1139	1135	1136	1134	1138	1156	1135	1139	1094	1103	1128	1127	1121	1138	1121	1121
				1120	1106	1117	1136	1100	1139	1090	1101	1101	1103	1097	1104	1108	1103	1106	1113	1125	1106
				1131	1110	1114	1135	1138	1128	1134	1127	1120	1122	1106	1113	1094	1107	1093	1093	1099	1120
				1115	1103	1057	1157	1155	1149	1135	1152	1122	1087	1107	1104	1103	1107	1106	1117	1108	1100
				1163	1075	1059	1132	1072	1148	1103	1124	1068	1092	1124	1127	1107	1121	1115	1121	1115	1092
				1124	1107	1103	1115	1114	1118	1121	1128	1122	1127	1117	1106	1127	1122	1128	1113	1103	1099
				1107	1114	1127	1117	1117	1111	1114	1113	1122	1106	1078	1083	1075	1076	1082	1127	1083	1114
				1106	1143	1097	1156	1145	1148	1118	1143	1131	1120	1096	1131	1118	1103	1118	1122	1128	1134
				1080	1120	1129	1114	1128	1110	1118	1115	1113	1122	1120	1078	1120	1127	1127	1073	1092	1092
				1113	1108	1111	1135	1142	1136	1135	1146	1132	1097	1142	1092	1087	1111	1104	1121	1117	1094
				1121	1092	1096	1086	1092	1076	1101	1128	1122	1117	1106	1121	1128	1108	1100	1075	1099	1113
				2560 2560 2560>;

			PS_Config_Lmt_FW_Rawdata_N = <
				456	489	485	467	490	471	474	483	(-65535)	(-65535)	465	467	469	476	459	468	462	462
				468	479	474	485	477	481	472	475	471	479	469	468	473	468	471	471	471	484
				474	486	486	483	483	480	486	481	471	480	469	482	478	475	475	469	470	478
				471	470	463	468	473	475	476	486	475	479	482	480	481	474	477	480	485	468
				466	486	493	496	490	489	492	487	465	477	487	471	474	485	473	478	471	488
				477	483	488	486	481	486	489	471	489	477	483	474	483	469	482	475	470	474
				475	478	478	474	472	469	472	471	478	480	474	476	468	486	477	475	477	477
				466	468	466	469	473	472	470	475	471	480	481	484	480	473	481	481	480	475
				466	478	486	475	484	479	490	465	481	480	484	480	475	470	477	475	483	483
				486	463	464	466	460	475	468	487	469	468	471	456	463	458	462	467	465	479
				487	466	468	465	464	473	468	486	472	480	482	481	478	477	483	484	487	480
				468	486	486	491	486	496	489	468	492	475	466	466	465	471	467	471	472	488
				472	490	489	478	492	472	471	472	484	472	484	459	457	455	457	454	450	489
				479	482	489	479	485	483	487	473	487	477	480	474	472	469	473	466	464	497
				467	493	494	484	485	457	457	460	484	472	481	476	478	482	481	474	467	474
				492	472	467	480	474	463	470	480	492	477	477	479	478	469	471	477	479	471
				471	472	468	463	469	475	477	472	471	474	472	468	474	471	474	466	473	474
				477	474	477	479	474	477	478	475	468	478	474	473	473	475	477	476	466	485
				466	491	486	486	482	481	490	483	490	490	476	481	472	465	474	468	476	475
				468	481	480	481	473	475	479	478	493	478	482	480	472	479	483	479	480	476
				466	490	481	486	483	486	482	483	470	460	481	468	496	505	496	501	495	482
				468	464	467	468	465	471	472	471	476	484	483	480	476	478	479	477	483	465
				482	478	482	486	481	488	484	489	490	475	476	478	482	484	480	480	483	476
				490	478	489	486	490	489	475	471	472	483	473	471	481	472	471	471	464	489
				484	473	472	475	484	483	477	478	489	477	483	485	475	474	474	470	472	472
				477	492	488	486	487	486	487	495	486	488	469	472	483	483	480	487	480	480
				480	474	478	487	471	488	467	472	472	472	470	473	475	472	474	477	482	474
				484	475	477	486	487	483	486	483	480	481	474	477	469	474	468	468	471	480
				478	472	453	496	495	492	486	493	481	466	474	473	472	474	474	478	475	471
				498	460	454	485	459	492	472	481	457	468	481	483	474	480	478	480	478	468
				481	474	472	478	477	479	480	483	481	483	478	474	483	481	483	477	472	471
				474	477	483	478	478	476	477	477	481	474	462	464	460	461	463	483	464	477
				474	490	470	495	490	492	479	490	484	480	469	484	479	472	479	481	483	486
				463	480	484	477	483	475	479	478	477	481	480	462	480	483	483	460	468	468
				477	475	476	486	489	487	486	491	485	470	489	468	466	476	473	480	478	469
				480	468	469	465	468	461	472	483	481	478	474	480	483	475	471	460	471	477
				240 240 240>;

			PS_Config_Lmt_FW_CC_P = <
				34	34	34	34	34	34	34	34	65535	65535	34	34	34	34	34	34	34	34
				34	33	34	33	33	34	34	34	35	35	34	34	34	34	34	34	34	34
				34	33	33	33	33	34	33	34	34	34	34	33	33	33	33	33	33	34
				34	33	34	34	33	34	34	34	34	34	33	33	33	33	33	33	33	34
				34	33	33	33	33	33	33	33	34	34	34	33	34	33	33	33	33	34
				34	34	34	34	34	34	34	34	35	34	34	34	34	34	34	34	34	34
				34	33	33	34	33	34	34	34	34	34	34	33	34	33	33	33	34	34
				34	34	34	34	33	34	34	34	35	34	34	34	34	34	34	34	34	34
				34	34	33	33	33	34	33	34	34	35	34	34	34	33	33	33	34	34
				34	34	34	34	34	34	34	34	35	34	34	34	34	34	34	34	34	34
				34	34	33	34	33	34	34	34	34	34	34	33	33	33	33	33	33	34
				34	33	33	33	33	34	34	34	35	34	34	34	34	33	34	33	33	34
				34	33	33	33	33	34	34	34	34	35	34	34	34	33	34	34	34	34
				34	34	34	34	33	34	34	34	35	35	34	34	34	33	34	34	34	34
				34	33	33	33	33	34	34	34	34	35	34	34	34	33	33	33	33	34
				34	33	34	34	34	34	34	34	35	35	34	34	34	34	34	33	33	34
				34	33	33	33	33	33	33	33	33	34	33	33	33	33	33	33	33	34
				34	34	34	34	34	34	34	34	34	34	34	34	34	33	33	33	34	34
				34	33	33	33	33	33	33	33	33	34	33	33	33	33	33	33	33	34
				34	34	33	33	33	33	34	34	34	34	34	34	33	33	34	34	34	34
				34	33	33	33	33	33	33	33	33	34	33	33	33	33	33	33	33	34
				34	34	33	33	33	33	34	34	34	34	33	33	33	33	33	33	33	34
				34	34	33	33	33	33	33	33	34	34	33	33	33	33	33	33	33	34
				34	34	33	33	33	33	33	34	34	34	34	34	33	33	34	34	34	34
				34	33	33	33	33	33	33	33	34	34	33	33	33	33	33	33	33	34
				34	33	33	33	33	33	33	33	34	34	33	33	33	33	33	33	33	34
				34	33	33	33	33	33	33	33	34	34	33	33	33	33	33	33	33	34
				34	33	33	33	33	33	33	33	34	34	33	34	33	33	33	34	34	34
				34	33	33	33	33	33	33	33	34	34	33	33	33	33	33	33	33	34
				34	33	34	33	34	33	33	33	35	34	33	33	33	34	33	34	33	34
				34	33	33	33	33	33	33	33	34	34	33	33	33	33	33	33	33	34
				34	33	33	33	33	33	33	33	34	34	33	34	33	33	33	34	34	34
				34	33	33	33	33	33	33	33	34	34	33	33	33	33	33	33	33	34
				34	33	34	33	34	33	34	34	35	34	33	33	33	33	33	34	33	34
				34	33	33	33	33	33	33	33	34	34	33	33	33	33	33	33	33	34
				34	34	34	33	34	34	34	34	35	34	33	33	33	33	33	34	34	34
				314 314 314>;

			PS_Config_Lmt_FW_CC_N = <
				15	15	15	15	15	15	15	15	(-65535)	(-65535)	15	15	15	15	15	15	15	15
				15	14	15	14	14	15	15	15	16	16	15	15	15	15	15	15	15	15
				15	14	14	14	14	15	14	15	15	15	15	14	14	14	14	14	14	15
				15	14	15	15	14	15	15	15	15	15	14	14	14	14	14	14	14	15
				15	14	14	14	14	14	14	14	15	15	15	14	15	14	14	14	14	15
				15	15	15	15	15	15	15	15	16	15	15	15	15	15	15	15	15	15
				15	14	14	15	14	15	15	15	15	15	15	14	15	14	14	14	15	15
				15	15	15	15	14	15	15	15	16	15	15	15	15	15	15	15	15	15
				15	15	14	14	14	15	14	15	15	16	15	15	15	14	14	14	15	15
				15	15	15	15	15	15	15	15	16	15	15	15	15	15	15	15	15	15
				15	15	14	15	14	15	15	15	15	15	15	14	14	14	14	14	14	15
				15	14	14	14	14	15	15	15	16	15	15	15	15	14	15	14	14	15
				15	14	14	14	14	15	15	15	15	16	15	15	15	14	15	15	15	15
				15	15	15	15	14	15	15	15	16	16	15	15	15	14	15	15	15	15
				15	14	14	14	14	15	15	15	15	16	15	15	15	14	14	14	14	15
				15	14	15	15	15	15	15	15	16	16	15	15	15	15	15	14	14	15
				15	14	14	14	14	14	14	14	14	15	14	14	14	14	14	14	14	15
				15	15	15	15	15	15	15	15	15	15	15	15	15	14	14	14	15	15
				15	14	14	14	14	14	14	14	14	15	14	14	14	14	14	14	14	15
				15	15	14	14	14	14	15	15	15	15	15	15	14	14	15	15	15	15
				15	14	14	14	14	14	14	14	14	15	14	14	14	14	14	14	14	15
				15	15	14	14	14	14	15	15	15	15	14	14	14	14	14	14	14	15
				15	15	14	14	14	14	14	14	15	15	14	14	14	14	14	14	14	15
				15	15	14	14	14	14	14	15	15	15	15	15	14	14	15	15	15	15
				15	14	14	14	14	14	14	14	15	15	14	14	14	14	14	14	14	15
				15	14	14	14	14	14	14	14	15	15	14	14	14	14	14	14	14	15
				15	14	14	14	14	14	14	14	15	15	14	14	14	14	14	14	14	15
				15	14	14	14	14	14	14	14	15	15	14	15	14	14	14	15	15	15
				15	14	14	14	14	14	14	14	15	15	14	14	14	14	14	14	14	15
				15	14	15	14	15	14	14	14	16	15	14	14	14	15	14	15	14	15
				15	14	14	14	14	14	14	14	15	15	14	14	14	14	14	14	14	15
				15	14	14	14	14	14	14	14	15	15	14	15	14	14	14	15	15	15
				15	14	14	14	14	14	14	14	15	15	14	14	14	14	14	14	14	15
				15	14	15	14	15	14	15	15	16	15	14	14	14	14	14	15	14	15
				15	14	14	14	14	14	14	14	15	15	14	14	14	14	14	14	14	15
				15	15	15	14	15	15	15	15	16	15	14	14	14	14	14	15	15	15
				0 0 0>;

			PS_Config_Lmt_FW_Diff_P = <
				50	50	50	50	50	50	50	50	65535	65535	50	50	50	50	50	50	50	50
				50	50	50	50	50	50	50	50	50	50	50	50	50	50	50	50	50	50
				50	50	50	50	50	50	50	50	50	50	50	50	50	50	50	50	50	50
				50	50	50	50	50	50	50	50	50	50	50	50	50	50	50	50	50	50
				50	50	50	50	50	50	50	50	50	50	50	50	50	50	50	50	50	50
				50	50	50	50	50	50	50	50	50	50	50	50	50	50	50	50	50	50
				50	50	50	50	50	50	50	50	50	50	50	50	50	50	50	50	50	50
				50	50	50	50	50	50	50	50	50	50	50	50	50	50	50	50	50	50
				50	50	50	50	50	50	50	50	50	50	50	50	50	50	50	50	50	50
				50	50	50	50	50	50	50	50	50	50	50	50	50	50	50	50	50	50
				50	50	50	50	50	50	50	50	50	50	50	50	50	50	50	50	50	50
				50	50	50	50	50	50	50	50	50	50	50	50	50	50	50	50	50	50
				50	50	50	50	50	50	50	50	50	50	50	50	50	50	50	50	50	50
				50	50	50	50	50	50	50	50	50	50	50	50	50	50	50	50	50	50
				50	50	50	50	50	50	50	50	50	50	50	50	50	50	50	50	50	50
				50	50	50	50	50	50	50	50	50	50	50	50	50	50	50	50	50	50
				50	50	50	50	50	50	50	50	50	50	50	50	50	50	50	50	50	50
				50	50	50	50	50	50	50	50	50	50	50	50	50	50	50	50	50	50
				50	50	50	50	50	50	50	50	50	50	50	50	50	50	50	50	50	50
				50	50	50	50	50	50	50	50	50	50	50	50	50	50	50	50	50	50
				50	50	50	50	50	50	50	50	50	50	50	50	50	50	50	50	50	50
				50	50	50	50	50	50	50	50	50	50	50	50	50	50	50	50	50	50
				50	50	50	50	50	50	50	50	50	50	50	50	50	50	50	50	50	50
				50	50	50	50	50	50	50	50	50	50	50	50	50	50	50	50	50	50
				50	50	50	50	50	50	50	50	50	50	50	50	50	50	50	50	50	50
				50	50	50	50	50	50	50	50	50	50	50	50	50	50	50	50	50	50
				50	50	50	50	50	50	50	50	50	50	50	50	50	50	50	50	50	50
				50	50	50	50	50	50	50	50	50	50	50	50	50	50	50	50	50	50
				50	50	50	50	50	50	50	50	50	50	50	50	50	50	50	50	50	50
				50	50	50	50	50	50	50	50	50	50	50	50	50	50	50	50	50	50
				50	50	50	50	50	50	50	50	50	50	50	50	50	50	50	50	50	50
				50	50	50	50	50	50	50	50	50	50	50	50	50	50	50	50	50	50
				50	50	50	50	50	50	50	50	50	50	50	50	50	50	50	50	50	50
				50	50	50	50	50	50	50	50	50	50	50	50	50	50	50	50	50	50
				50	50	50	50	50	50	50	50	50	50	50	50	50	50	50	50	50	50
				50	50	50	50	50	50	50	50	50	50	50	50	50	50	50	50	50	50
				75 75 75>;

			PS_Config_Lmt_FW_Diff_N = <
				(-50)	(-50)	(-50)	(-50)	(-50)	(-50)	(-50)	(-50)	(-65535)	(-65535)	(-50)	(-50)	(-50)	(-50)	(-50)	(-50)	(-50)	(-50)
				(-50)	(-50)	(-50)	(-50)	(-50)	(-50)	(-50)	(-50)	(-50)	(-50)	(-50)	(-50)	(-50)	(-50)	(-50)	(-50)	(-50)	(-50)
				(-50)	(-50)	(-50)	(-50)	(-50)	(-50)	(-50)	(-50)	(-50)	(-50)	(-50)	(-50)	(-50)	(-50)	(-50)	(-50)	(-50)	(-50)
				(-50)	(-50)	(-50)	(-50)	(-50)	(-50)	(-50)	(-50)	(-50)	(-50)	(-50)	(-50)	(-50)	(-50)	(-50)	(-50)	(-50)	(-50)
				(-50)	(-50)	(-50)	(-50)	(-50)	(-50)	(-50)	(-50)	(-50)	(-50)	(-50)	(-50)	(-50)	(-50)	(-50)	(-50)	(-50)	(-50)
				(-50)	(-50)	(-50)	(-50)	(-50)	(-50)	(-50)	(-50)	(-50)	(-50)	(-50)	(-50)	(-50)	(-50)	(-50)	(-50)	(-50)	(-50)
				(-50)	(-50)	(-50)	(-50)	(-50)	(-50)	(-50)	(-50)	(-50)	(-50)	(-50)	(-50)	(-50)	(-50)	(-50)	(-50)	(-50)	(-50)
				(-50)	(-50)	(-50)	(-50)	(-50)	(-50)	(-50)	(-50)	(-50)	(-50)	(-50)	(-50)	(-50)	(-50)	(-50)	(-50)	(-50)	(-50)
				(-50)	(-50)	(-50)	(-50)	(-50)	(-50)	(-50)	(-50)	(-50)	(-50)	(-50)	(-50)	(-50)	(-50)	(-50)	(-50)	(-50)	(-50)
				(-50)	(-50)	(-50)	(-50)	(-50)	(-50)	(-50)	(-50)	(-50)	(-50)	(-50)	(-50)	(-50)	(-50)	(-50)	(-50)	(-50)	(-50)
				(-50)	(-50)	(-50)	(-50)	(-50)	(-50)	(-50)	(-50)	(-50)	(-50)	(-50)	(-50)	(-50)	(-50)	(-50)	(-50)	(-50)	(-50)
				(-50)	(-50)	(-50)	(-50)	(-50)	(-50)	(-50)	(-50)	(-50)	(-50)	(-50)	(-50)	(-50)	(-50)	(-50)	(-50)	(-50)	(-50)
				(-50)	(-50)	(-50)	(-50)	(-50)	(-50)	(-50)	(-50)	(-50)	(-50)	(-50)	(-50)	(-50)	(-50)	(-50)	(-50)	(-50)	(-50)
				(-50)	(-50)	(-50)	(-50)	(-50)	(-50)	(-50)	(-50)	(-50)	(-50)	(-50)	(-50)	(-50)	(-50)	(-50)	(-50)	(-50)	(-50)
				(-50)	(-50)	(-50)	(-50)	(-50)	(-50)	(-50)	(-50)	(-50)	(-50)	(-50)	(-50)	(-50)	(-50)	(-50)	(-50)	(-50)	(-50)
				(-50)	(-50)	(-50)	(-50)	(-50)	(-50)	(-50)	(-50)	(-50)	(-50)	(-50)	(-50)	(-50)	(-50)	(-50)	(-50)	(-50)	(-50)
				(-50)	(-50)	(-50)	(-50)	(-50)	(-50)	(-50)	(-50)	(-50)	(-50)	(-50)	(-50)	(-50)	(-50)	(-50)	(-50)	(-50)	(-50)
				(-50)	(-50)	(-50)	(-50)	(-50)	(-50)	(-50)	(-50)	(-50)	(-50)	(-50)	(-50)	(-50)	(-50)	(-50)	(-50)	(-50)	(-50)
				(-50)	(-50)	(-50)	(-50)	(-50)	(-50)	(-50)	(-50)	(-50)	(-50)	(-50)	(-50)	(-50)	(-50)	(-50)	(-50)	(-50)	(-50)
				(-50)	(-50)	(-50)	(-50)	(-50)	(-50)	(-50)	(-50)	(-50)	(-50)	(-50)	(-50)	(-50)	(-50)	(-50)	(-50)	(-50)	(-50)
				(-50)	(-50)	(-50)	(-50)	(-50)	(-50)	(-50)	(-50)	(-50)	(-50)	(-50)	(-50)	(-50)	(-50)	(-50)	(-50)	(-50)	(-50)
				(-50)	(-50)	(-50)	(-50)	(-50)	(-50)	(-50)	(-50)	(-50)	(-50)	(-50)	(-50)	(-50)	(-50)	(-50)	(-50)	(-50)	(-50)
				(-50)	(-50)	(-50)	(-50)	(-50)	(-50)	(-50)	(-50)	(-50)	(-50)	(-50)	(-50)	(-50)	(-50)	(-50)	(-50)	(-50)	(-50)
				(-50)	(-50)	(-50)	(-50)	(-50)	(-50)	(-50)	(-50)	(-50)	(-50)	(-50)	(-50)	(-50)	(-50)	(-50)	(-50)	(-50)	(-50)
				(-50)	(-50)	(-50)	(-50)	(-50)	(-50)	(-50)	(-50)	(-50)	(-50)	(-50)	(-50)	(-50)	(-50)	(-50)	(-50)	(-50)	(-50)
				(-50)	(-50)	(-50)	(-50)	(-50)	(-50)	(-50)	(-50)	(-50)	(-50)	(-50)	(-50)	(-50)	(-50)	(-50)	(-50)	(-50)	(-50)
				(-50)	(-50)	(-50)	(-50)	(-50)	(-50)	(-50)	(-50)	(-50)	(-50)	(-50)	(-50)	(-50)	(-50)	(-50)	(-50)	(-50)	(-50)
				(-50)	(-50)	(-50)	(-50)	(-50)	(-50)	(-50)	(-50)	(-50)	(-50)	(-50)	(-50)	(-50)	(-50)	(-50)	(-50)	(-50)	(-50)
				(-50)	(-50)	(-50)	(-50)	(-50)	(-50)	(-50)	(-50)	(-50)	(-50)	(-50)	(-50)	(-50)	(-50)	(-50)	(-50)	(-50)	(-50)
				(-50)	(-50)	(-50)	(-50)	(-50)	(-50)	(-50)	(-50)	(-50)	(-50)	(-50)	(-50)	(-50)	(-50)	(-50)	(-50)	(-50)	(-50)
				(-50)	(-50)	(-50)	(-50)	(-50)	(-50)	(-50)	(-50)	(-50)	(-50)	(-50)	(-50)	(-50)	(-50)	(-50)	(-50)	(-50)	(-50)
				(-50)	(-50)	(-50)	(-50)	(-50)	(-50)	(-50)	(-50)	(-50)	(-50)	(-50)	(-50)	(-50)	(-50)	(-50)	(-50)	(-50)	(-50)
				(-50)	(-50)	(-50)	(-50)	(-50)	(-50)	(-50)	(-50)	(-50)	(-50)	(-50)	(-50)	(-50)	(-50)	(-50)	(-50)	(-50)	(-50)
				(-50)	(-50)	(-50)	(-50)	(-50)	(-50)	(-50)	(-50)	(-50)	(-50)	(-50)	(-50)	(-50)	(-50)	(-50)	(-50)	(-50)	(-50)
				(-50)	(-50)	(-50)	(-50)	(-50)	(-50)	(-50)	(-50)	(-50)	(-50)	(-50)	(-50)	(-50)	(-50)	(-50)	(-50)	(-50)	(-50)
				(-50)	(-50)	(-50)	(-50)	(-50)	(-50)	(-50)	(-50)	(-50)	(-50)	(-50)	(-50)	(-50)	(-50)	(-50)	(-50)	(-50)	(-50)
				(-75) (-75) (-75)>;

			PS_Config_Diff_Test_Frame = <50>;
		};

	};

	/*
	focaltech@0 {
			compatible = "focaltech8719P,FTS-ts-spi";
			reg = <0>;
			spi-max-frequency = <8000000>;
			interrupt-parent = <&pio>;
			interrupts = <1 0x2>;
			focaltech,reset-gpio = <&pio 92 0x00>;
			focaltech,irq-gpio = <&pio 1 0x2001>;
			focaltech,max-touch-number = <10>;
			focaltech,display-coords =  <0 0 1080 2340>;
		};
	*/
};

/* DISPSYS GPIO standardization end*/

#include <lancelot/cust.dtsi>
#include "mediatek/cust_mt6768_lancelot_camera.dtsi"
/*End of this file, DO NOT ADD ANYTHING HERE*/
